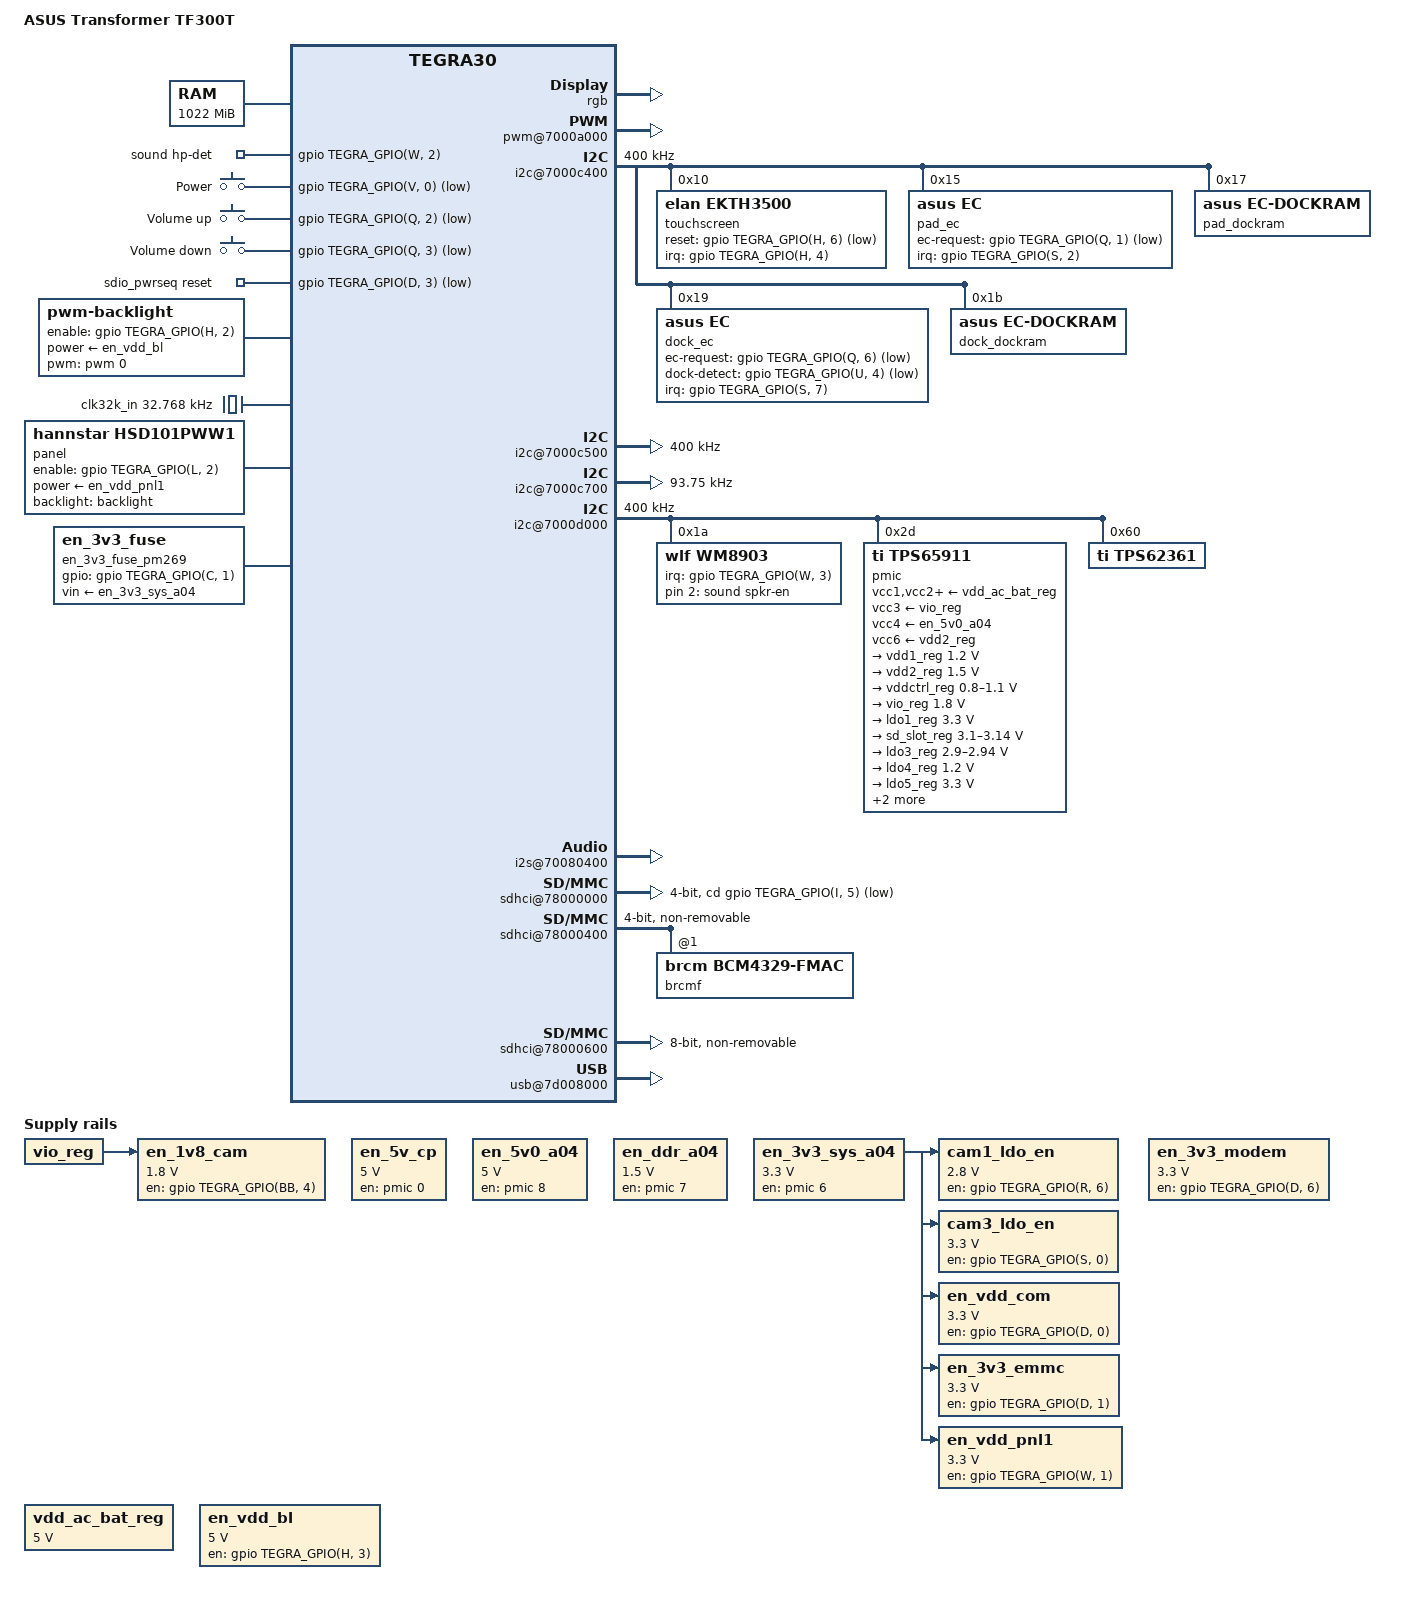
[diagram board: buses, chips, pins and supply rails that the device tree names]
/dts-v1/;

#include "tegra30.dtsi"

/ {
	model = "ASUS Transformer TF300T";
	compatible = "asus,tf300t", "nvidia,tegra30";

	memory {
		reg = <0x80000000 0x3FE00000>;
	};

	/*pcie-controller@00003000 {
		status = "okay";

		/* AVDD_PEXA and VDD_PEXA inputs are grounded on Cardhu. * /
		avdd-pexb-supply = <&ldo1_reg>;
		vdd-pexb-supply = <&ldo1_reg>;
		avdd-pex-pll-supply = <&ldo1_reg>;
		hvdd-pex-supply = <&pex_hvdd_3v3_reg>;
		vddio-pex-ctl-supply = <&sys_3v3_reg>;
		avdd-plle-supply = <&ldo2_reg>;

		pci@1,0 {
			nvidia,num-lanes = <4>;
		};

		pci@2,0 {
			nvidia,num-lanes = <1>;
		};

		pci@3,0 {
			status = "okay";
			nvidia,num-lanes = <1>;
		};
	};*/

	/* FIXME: broken */
	/delete-node/ cache-controller@50043000;

	cache-controller@50043000 {
		compatible = "arm,pl310-cache-nonsecure";
		reg = <0x50043000 0x1000>;
		arm,data-latency = <6 6 2>;
		arm,tag-latency = <5 5 2>;
		cache-unified;
		cache-level = <2>;
	};

	firmware {
		trusted-foundations {
			compatible = "tlm,trusted-foundations";
			tlm,version-major = <2>;
			tlm,version-minor = <8>;
		};
	};

	host1x@50000000 {
		dc@54200000 {
			rgb {
				status = "okay";

				nvidia,panel = <&panel>;
			};
		};
	};

	/*pinmux@70000868 {
		pinctrl-names = "default";
		pinctrl-0 = <&state_default>;

		state_default: pinmux {
			sdmmc1_clk_pz0 {
				nvidia,pins = "sdmmc1_clk_pz0";
				nvidia,function = "sdmmc1";
				nvidia,pull = <TEGRA_PIN_PULL_NONE>;
				nvidia,tristate = <TEGRA_PIN_DISABLE>;
				nvidia,enable-input = <TEGRA_PIN_ENABLE>;
			};
			sdmmc1_cmd_pz1 {
				nvidia,pins = "sdmmc1_cmd_pz1";
				nvidia,function = "sdmmc1";
				nvidia,pull = <TEGRA_PIN_PULL_UP>;
				nvidia,tristate = <TEGRA_PIN_DISABLE>;
				nvidia,enable-input = <TEGRA_PIN_ENABLE>;
			};
			sdmmc1_dat3_py4 {
				nvidia,pins = "sdmmc1_dat3_py4";
				nvidia,function = "sdmmc1";
				nvidia,pull = <TEGRA_PIN_PULL_UP>;
				nvidia,tristate = <TEGRA_PIN_DISABLE>;
				nvidia,enable-input = <TEGRA_PIN_ENABLE>;
			};
			sdmmc1_dat2_py5 {
				nvidia,pins = "sdmmc1_dat2_py5";
				nvidia,function = "sdmmc1";
				nvidia,pull = <TEGRA_PIN_PULL_UP>;
				nvidia,tristate = <TEGRA_PIN_DISABLE>;
				nvidia,enable-input = <TEGRA_PIN_ENABLE>;
			};
			sdmmc1_dat1_py6 {
				nvidia,pins = "sdmmc1_dat1_py6";
				nvidia,function = "sdmmc1";
				nvidia,pull = <TEGRA_PIN_PULL_UP>;
				nvidia,tristate = <TEGRA_PIN_DISABLE>;
				nvidia,enable-input = <TEGRA_PIN_ENABLE>;
			};
			sdmmc1_dat0_py7 {
				nvidia,pins = "sdmmc1_dat0_py7";
				nvidia,function = "sdmmc1";
				nvidia,pull = <TEGRA_PIN_PULL_UP>;
				nvidia,tristate = <TEGRA_PIN_DISABLE>;
				nvidia,enable-input = <TEGRA_PIN_ENABLE>;
			};
			sdmmc3_clk_pa6 {
				nvidia,pins = "sdmmc3_clk_pa6";
				nvidia,function = "sdmmc3";
				nvidia,pull = <TEGRA_PIN_PULL_NONE>;
				nvidia,tristate = <TEGRA_PIN_DISABLE>;
				nvidia,enable-input = <TEGRA_PIN_ENABLE>;
			};
			sdmmc3_cmd_pa7 {
				nvidia,pins = "sdmmc3_cmd_pa7";
				nvidia,function = "sdmmc3";
				nvidia,pull = <TEGRA_PIN_PULL_UP>;
				nvidia,tristate = <TEGRA_PIN_DISABLE>;
				nvidia,enable-input = <TEGRA_PIN_ENABLE>;
			};
			sdmmc3_dat0_pb7 {
				nvidia,pins = "sdmmc3_dat0_pb7";
				nvidia,function = "sdmmc3";
				nvidia,pull = <TEGRA_PIN_PULL_UP>;
				nvidia,tristate = <TEGRA_PIN_DISABLE>;
				nvidia,enable-input = <TEGRA_PIN_ENABLE>;
			};
			sdmmc3_dat1_pb6 {
				nvidia,pins = "sdmmc3_dat1_pb6";
				nvidia,function = "sdmmc3";
				nvidia,pull = <TEGRA_PIN_PULL_UP>;
				nvidia,tristate = <TEGRA_PIN_DISABLE>;
				nvidia,enable-input = <TEGRA_PIN_ENABLE>;
			};
			sdmmc3_dat2_pb5 {
				nvidia,pins = "sdmmc3_dat2_pb5";
				nvidia,function = "sdmmc3";
				nvidia,pull = <TEGRA_PIN_PULL_UP>;
				nvidia,tristate = <TEGRA_PIN_DISABLE>;
				nvidia,enable-input = <TEGRA_PIN_ENABLE>;
			};
			sdmmc3_dat3_pb4 {
				nvidia,pins = "sdmmc3_dat3_pb4";
				nvidia,function = "sdmmc3";
				nvidia,pull = <TEGRA_PIN_PULL_UP>;
				nvidia,tristate = <TEGRA_PIN_DISABLE>;
				nvidia,enable-input = <TEGRA_PIN_ENABLE>;
			};
			sdmmc3_dat6_pd3 {
				nvidia,pins = "sdmmc3_dat6_pd3";
				nvidia,function = "sdmmc3";
				nvidia,pull = <TEGRA_PIN_PULL_UP>;
				nvidia,tristate = <TEGRA_PIN_DISABLE>;
				/* WLAN RESET * /
				nvidia,enable-input = <TEGRA_PIN_ENABLE>;
				/*nvidia,enable-input = <TEGRA_PIN_DISABLE>;* /
			};
			sdmmc3_dat7_pd4 {
				nvidia,pins = "sdmmc3_dat7_pd4";
				nvidia,function = "sdmmc3";
				nvidia,pull = <TEGRA_PIN_PULL_UP>;
				nvidia,tristate = <TEGRA_PIN_DISABLE>;
				/* WLAN POWER * /
				nvidia,enable-input = <TEGRA_PIN_ENABLE>;
				/*nvidia,enable-input = <TEGRA_PIN_DISABLE>;* /
			};
			sdmmc4_clk_pcc4 {
				nvidia,pins = "sdmmc4_clk_pcc4";
				nvidia,function = "sdmmc4";
				nvidia,pull = <TEGRA_PIN_PULL_NONE>;
				nvidia,tristate = <TEGRA_PIN_DISABLE>;
				nvidia,enable-input = <TEGRA_PIN_ENABLE>;
			};
			sdmmc4_cmd_pt7 {
				nvidia,pins = "sdmmc4_cmd_pt7";
				nvidia,function = "sdmmc4";
				nvidia,pull = <TEGRA_PIN_PULL_UP>;
				nvidia,tristate = <TEGRA_PIN_DISABLE>;
				nvidia,enable-input = <TEGRA_PIN_ENABLE>;
			};
			sdmmc4_dat0_paa0 {
				nvidia,pins = "sdmmc4_dat0_paa0";
				nvidia,function = "sdmmc4";
				nvidia,pull = <TEGRA_PIN_PULL_UP>;
				nvidia,tristate = <TEGRA_PIN_DISABLE>;
				nvidia,enable-input = <TEGRA_PIN_ENABLE>;
			};
			sdmmc4_dat1_paa1 {
				nvidia,pins = "sdmmc4_dat1_paa1";
				nvidia,function = "sdmmc4";
				nvidia,pull = <TEGRA_PIN_PULL_UP>;
				nvidia,tristate = <TEGRA_PIN_DISABLE>;
				nvidia,enable-input = <TEGRA_PIN_ENABLE>;
			};
			sdmmc4_dat2_paa2 {
				nvidia,pins = "sdmmc4_dat2_paa2";
				nvidia,function = "sdmmc4";
				nvidia,pull = <TEGRA_PIN_PULL_UP>;
				nvidia,tristate = <TEGRA_PIN_DISABLE>;
				nvidia,enable-input = <TEGRA_PIN_ENABLE>;
			};
			sdmmc4_dat3_paa3 {
				nvidia,pins = "sdmmc4_dat3_paa3";
				nvidia,function = "sdmmc4";
				nvidia,pull = <TEGRA_PIN_PULL_UP>;
				nvidia,tristate = <TEGRA_PIN_DISABLE>;
				nvidia,enable-input = <TEGRA_PIN_ENABLE>;
			};
			sdmmc4_dat4_paa4 {
				nvidia,pins = "sdmmc4_dat4_paa4";
				nvidia,function = "sdmmc4";
				nvidia,pull = <TEGRA_PIN_PULL_UP>;
				nvidia,tristate = <TEGRA_PIN_DISABLE>;
				nvidia,enable-input = <TEGRA_PIN_ENABLE>;
			};
			sdmmc4_dat5_paa5 {
				nvidia,pins = "sdmmc4_dat5_paa5";
				nvidia,function = "sdmmc4";
				nvidia,pull = <TEGRA_PIN_PULL_UP>;
				nvidia,tristate = <TEGRA_PIN_DISABLE>;
				nvidia,enable-input = <TEGRA_PIN_ENABLE>;
			};
			sdmmc4_dat6_paa6 {
				nvidia,pins = "sdmmc4_dat6_paa6";
				nvidia,function = "sdmmc4";
				nvidia,pull = <TEGRA_PIN_PULL_UP>;
				nvidia,tristate = <TEGRA_PIN_DISABLE>;
				nvidia,enable-input = <TEGRA_PIN_ENABLE>;
			};
			sdmmc4_dat7_paa7 {
				nvidia,pins = "sdmmc4_dat7_paa7";
				nvidia,function = "sdmmc4";
				nvidia,pull = <TEGRA_PIN_PULL_UP>;
				nvidia,tristate = <TEGRA_PIN_DISABLE>;
				nvidia,enable-input = <TEGRA_PIN_ENABLE>;
			};
			sdmmc4_rst_n_pcc3 {
				nvidia,pins = "sdmmc4_rst_n_pcc3";
				nvidia,function = "rsvd1";
				nvidia,pull = <TEGRA_PIN_PULL_DOWN>;
				nvidia,tristate = <TEGRA_PIN_DISABLE>;
				nvidia,enable-input = <TEGRA_PIN_ENABLE>;
			};
			gen1_i2c_scl_pc4 {
				nvidia,pins = "gen1_i2c_scl_pc4";
				nvidia,function = "i2c1";
				nvidia,pull = <TEGRA_PIN_PULL_NONE>;
				nvidia,tristate = <TEGRA_PIN_DISABLE>;
				nvidia,enable-input = <TEGRA_PIN_ENABLE>;
				nvidia,lock = <TEGRA_PIN_DISABLE>;
				nvidia,open-drain = <TEGRA_PIN_ENABLE>;
			};
			gen1_i2c_sda_pc5 {
				nvidia,pins = "gen1_i2c_sda_pc5";
				nvidia,function = "i2c1";
				nvidia,pull = <TEGRA_PIN_PULL_NONE>;
				nvidia,tristate = <TEGRA_PIN_DISABLE>;
				nvidia,enable-input = <TEGRA_PIN_ENABLE>;
				nvidia,lock = <TEGRA_PIN_DISABLE>;
				nvidia,open-drain = <TEGRA_PIN_ENABLE>;
			};
			gen2_i2c_scl_pt5 {
				nvidia,pins = "gen2_i2c_scl_pt5";
				nvidia,function = "i2c2";
				nvidia,pull = <TEGRA_PIN_PULL_NONE>;
				nvidia,tristate = <TEGRA_PIN_DISABLE>;
				nvidia,enable-input = <TEGRA_PIN_ENABLE>;
				nvidia,lock = <TEGRA_PIN_DISABLE>;
				nvidia,open-drain = <TEGRA_PIN_ENABLE>;
			};
			gen2_i2c_sda_pt6 {
				nvidia,pins = "gen2_i2c_sda_pt6";
				nvidia,function = "i2c2";
				nvidia,pull = <TEGRA_PIN_PULL_NONE>;
				nvidia,tristate = <TEGRA_PIN_DISABLE>;
				nvidia,enable-input = <TEGRA_PIN_ENABLE>;
				nvidia,lock = <TEGRA_PIN_DISABLE>;
				nvidia,open-drain = <TEGRA_PIN_ENABLE>;
			};
			cam_i2c_scl_pbb1 {
				nvidia,pins = "cam_i2c_scl_pbb1";
				nvidia,function = "i2c3";
				nvidia,pull = <TEGRA_PIN_PULL_NONE>;
				nvidia,tristate = <TEGRA_PIN_DISABLE>;
				nvidia,enable-input = <TEGRA_PIN_ENABLE>;
				nvidia,lock = <TEGRA_PIN_DISABLE>;
				nvidia,open-drain = <TEGRA_PIN_ENABLE>;
			};
			cam_i2c_sda_pbb2 {
				nvidia,pins = "cam_i2c_sda_pbb2";
				nvidia,function = "i2c3";
				nvidia,pull = <TEGRA_PIN_PULL_NONE>;
				nvidia,tristate = <TEGRA_PIN_DISABLE>;
				nvidia,enable-input = <TEGRA_PIN_ENABLE>;
				nvidia,lock = <TEGRA_PIN_DISABLE>;
				nvidia,open-drain = <TEGRA_PIN_ENABLE>;
			};
			ddc_scl_pv4 {
				nvidia,pins = "ddc_scl_pv4";
				nvidia,function = "i2c4";
				nvidia,pull = <TEGRA_PIN_PULL_NONE>;
				nvidia,tristate = <TEGRA_PIN_DISABLE>;
				nvidia,enable-input = <TEGRA_PIN_ENABLE>;
				nvidia,lock = <TEGRA_PIN_DISABLE>;
				nvidia,open-drain = <TEGRA_PIN_ENABLE>;
			};
			ddc_sda_pv5 {
				nvidia,pins = "ddc_sda_pv5";
				nvidia,function = "i2c4";
				nvidia,pull = <TEGRA_PIN_PULL_NONE>;
				nvidia,tristate = <TEGRA_PIN_DISABLE>;
				nvidia,enable-input = <TEGRA_PIN_ENABLE>;
				nvidia,lock = <TEGRA_PIN_DISABLE>;
				nvidia,open-drain = <TEGRA_PIN_ENABLE>;
			};
			pwr_i2c_scl_pz6 {
				nvidia,pins = "pwr_i2c_scl_pz6";
				nvidia,function = "i2cpwr";
				nvidia,pull = <TEGRA_PIN_PULL_NONE>;
				nvidia,tristate = <TEGRA_PIN_DISABLE>;
				nvidia,enable-input = <TEGRA_PIN_ENABLE>;
				nvidia,lock = <TEGRA_PIN_DISABLE>;
				nvidia,open-drain = <TEGRA_PIN_ENABLE>;
			};
			pwr_i2c_sda_pz7 {
				nvidia,pins = "pwr_i2c_sda_pz7";
				nvidia,function = "i2cpwr";
				nvidia,pull = <TEGRA_PIN_PULL_NONE>;
				nvidia,tristate = <TEGRA_PIN_DISABLE>;
				nvidia,enable-input = <TEGRA_PIN_ENABLE>;
				nvidia,lock = <TEGRA_PIN_DISABLE>;
				nvidia,open-drain = <TEGRA_PIN_ENABLE>;
			};
			hdmi_cec_pee3 {
				nvidia,pins = "hdmi_cec_pee3";
				nvidia,function = "cec";
				nvidia,pull = <TEGRA_PIN_PULL_NONE>;
				nvidia,tristate = <TEGRA_PIN_DISABLE>;
				nvidia,enable-input = <TEGRA_PIN_ENABLE>;
			};
			ulpi_data0_po1 {
				nvidia,pins = "ulpi_data0_po1";
				nvidia,function = "uarta";
				nvidia,pull = <TEGRA_PIN_PULL_NONE>;
				nvidia,tristate = <TEGRA_PIN_DISABLE>;
				nvidia,enable-input = <TEGRA_PIN_DISABLE>;
			};
			ulpi_data1_po2 {
				nvidia,pins = "ulpi_data1_po2";
				nvidia,function = "uarta";
				nvidia,pull = <TEGRA_PIN_PULL_DOWN>;
				nvidia,tristate = <TEGRA_PIN_ENABLE>;
				nvidia,enable-input = <TEGRA_PIN_ENABLE>;
			};
			ulpi_data2_po3 {
				nvidia,pins = "ulpi_data2_po3";
				nvidia,function = "uarta";
				nvidia,pull = <TEGRA_PIN_PULL_NONE>;
				nvidia,tristate = <TEGRA_PIN_DISABLE>;
				nvidia,enable-input = <TEGRA_PIN_ENABLE>;
			};
			ulpi_data3_po4 {
				nvidia,pins = "ulpi_data3_po4";
				nvidia,function = "uarta";
				nvidia,pull = <TEGRA_PIN_PULL_NONE>;
				nvidia,tristate = <TEGRA_PIN_DISABLE>;
				nvidia,enable-input = <TEGRA_PIN_ENABLE>;
			};
			ulpi_data4_po5 {
				nvidia,pins = "ulpi_data4_po5";
				nvidia,function = "uarta";
				nvidia,pull = <TEGRA_PIN_PULL_NONE>;
				nvidia,tristate = <TEGRA_PIN_DISABLE>;
				nvidia,enable-input = <TEGRA_PIN_ENABLE>;
			};
			ulpi_data5_po6 {
				nvidia,pins = "ulpi_data5_po6";
				nvidia,function = "uarta";
				nvidia,pull = <TEGRA_PIN_PULL_NONE>;
				nvidia,tristate = <TEGRA_PIN_ENABLE>;
				nvidia,enable-input = <TEGRA_PIN_ENABLE>;
			};
			ulpi_data6_po7 {
				nvidia,pins = "ulpi_data6_po7";
				nvidia,function = "uarta";
				nvidia,pull = <TEGRA_PIN_PULL_NONE>;
				nvidia,tristate = <TEGRA_PIN_DISABLE>;
				nvidia,enable-input = <TEGRA_PIN_ENABLE>;
			};
			ulpi_data7_po0 {
				nvidia,pins = "ulpi_data7_po0";
				nvidia,function = "uarta";
				nvidia,pull = <TEGRA_PIN_PULL_NONE>;
				nvidia,tristate = <TEGRA_PIN_DISABLE>;
				nvidia,enable-input = <TEGRA_PIN_ENABLE>;
			};
			ulpi_nxt_py2 {
				nvidia,pins = "ulpi_nxt_py2";
				nvidia,function = "uartd";
				nvidia,pull = <TEGRA_PIN_PULL_NONE>;
				nvidia,tristate = <TEGRA_PIN_ENABLE>;
				nvidia,enable-input = <TEGRA_PIN_ENABLE>;
			};
			ulpi_stp_py3 {
				nvidia,pins = "ulpi_stp_py3";
				nvidia,function = "uartd";
				nvidia,pull = <TEGRA_PIN_PULL_NONE>;
				nvidia,tristate = <TEGRA_PIN_ENABLE>;
				nvidia,enable-input = <TEGRA_PIN_DISABLE>;
			};
			dap3_fs_pp0 {
				nvidia,pins = "dap3_fs_pp0";
				nvidia,function = "i2s2";
				nvidia,pull = <TEGRA_PIN_PULL_NONE>;
				nvidia,tristate = <TEGRA_PIN_ENABLE>;
				nvidia,enable-input = <TEGRA_PIN_ENABLE>;
			};
			dap3_din_pp1 {
				nvidia,pins = "dap3_din_pp1";
				nvidia,function = "i2s2";
				nvidia,pull = <TEGRA_PIN_PULL_NONE>;
				nvidia,tristate = <TEGRA_PIN_ENABLE>;
				nvidia,enable-input = <TEGRA_PIN_ENABLE>;
			};
			dap3_dout_pp2 {
				nvidia,pins = "dap3_dout_pp2";
				nvidia,function = "i2s2";
				nvidia,pull = <TEGRA_PIN_PULL_NONE>;
				nvidia,tristate = <TEGRA_PIN_DISABLE>;
				nvidia,enable-input = <TEGRA_PIN_ENABLE>;
			};
			dap3_sclk_pp3 {
				nvidia,pins = "dap3_sclk_pp3";
				nvidia,function = "i2s2";
				nvidia,pull = <TEGRA_PIN_PULL_NONE>;
				nvidia,tristate = <TEGRA_PIN_DISABLE>;
				nvidia,enable-input = <TEGRA_PIN_ENABLE>;
			};
			pv2 {
				nvidia,pins = "pv2";
				nvidia,function = "rsvd1";
				nvidia,pull = <TEGRA_PIN_PULL_NONE>;
				nvidia,tristate = <TEGRA_PIN_DISABLE>;
				nvidia,enable-input = <TEGRA_PIN_DISABLE>;
			};
			pv3 {
				nvidia,pins = "pv3";
				nvidia,function = "rsvd1";
				nvidia,pull = <TEGRA_PIN_PULL_NONE>;
				nvidia,tristate = <TEGRA_PIN_ENABLE>;
				nvidia,enable-input = <TEGRA_PIN_DISABLE>;
			};
			clk2_out_pw5 {
				nvidia,pins = "clk2_out_pw5";
				nvidia,function = "extperiph2";
				nvidia,pull = <TEGRA_PIN_PULL_NONE>;
				nvidia,tristate = <TEGRA_PIN_DISABLE>;
				nvidia,enable-input = <TEGRA_PIN_ENABLE>;
			};
			clk2_req_pcc5 {
				nvidia,pins = "clk2_req_pcc5";
				nvidia,function = "dap";
				nvidia,pull = <TEGRA_PIN_PULL_NONE>;
				nvidia,tristate = <TEGRA_PIN_DISABLE>;
				nvidia,enable-input = <TEGRA_PIN_ENABLE>;
			};
			lcd_pwr1_pc1 {
				nvidia,pins = "lcd_pwr1_pc1";
				nvidia,function = "displaya";
				nvidia,pull = <TEGRA_PIN_PULL_NONE>;
				nvidia,tristate = <TEGRA_PIN_DISABLE>;
				nvidia,enable-input = <TEGRA_PIN_ENABLE>;
			};
			lcd_sdin_pz2 {
				nvidia,pins = "lcd_sdin_pz2";
				nvidia,function = "displaya";
				nvidia,pull = <TEGRA_PIN_PULL_NONE>;
				nvidia,tristate = <TEGRA_PIN_DISABLE>;
				nvidia,enable-input = <TEGRA_PIN_ENABLE>;
			};
			lcd_sdout_pn5 {
				nvidia,pins = "lcd_sdout_pn5";
				nvidia,function = "displaya";
				nvidia,pull = <TEGRA_PIN_PULL_NONE>;
				nvidia,tristate = <TEGRA_PIN_ENABLE>;
				nvidia,enable-input = <TEGRA_PIN_ENABLE>;
			};
			lcd_wr_n_pz3 {
				nvidia,pins = "lcd_wr_n_pz3";
				nvidia,function = "displaya";
				nvidia,pull = <TEGRA_PIN_PULL_NONE>;
				nvidia,tristate = <TEGRA_PIN_ENABLE>;
				nvidia,enable-input = <TEGRA_PIN_ENABLE>;
			};
			lcd_dc0_pn6 {
				nvidia,pins = "lcd_dc0_pn6";
				nvidia,function = "displaya";
				nvidia,pull = <TEGRA_PIN_PULL_NONE>;
				nvidia,tristate = <TEGRA_PIN_DISABLE>;
				nvidia,enable-input = <TEGRA_PIN_ENABLE>;
			};
			lcd_pwr0_pb2 {
				nvidia,pins = "lcd_pwr0_pb2";
				nvidia,function = "displaya";
				nvidia,pull = <TEGRA_PIN_PULL_NONE>;
				nvidia,tristate = <TEGRA_PIN_DISABLE>;
				nvidia,enable-input = <TEGRA_PIN_ENABLE>;
			};
			lcd_pclk_pb3 {
				nvidia,pins = "lcd_pclk_pb3";
				nvidia,function = "displaya";
				nvidia,pull = <TEGRA_PIN_PULL_NONE>;
				nvidia,tristate = <TEGRA_PIN_DISABLE>;
				nvidia,enable-input = <TEGRA_PIN_ENABLE>;
			};
			lcd_de_pj1 {
				nvidia,pins = "lcd_de_pj1";
				nvidia,function = "displaya";
				nvidia,pull = <TEGRA_PIN_PULL_NONE>;
				nvidia,tristate = <TEGRA_PIN_DISABLE>;
				nvidia,enable-input = <TEGRA_PIN_ENABLE>;
			};
			lcd_hsync_pj3 {
				nvidia,pins = "lcd_hsync_pj3";
				nvidia,function = "displaya";
				nvidia,pull = <TEGRA_PIN_PULL_NONE>;
				nvidia,tristate = <TEGRA_PIN_DISABLE>;
				nvidia,enable-input = <TEGRA_PIN_ENABLE>;
			};
			lcd_vsync_pj4 {
				nvidia,pins = "lcd_vsync_pj4";
				nvidia,function = "displaya";
				nvidia,pull = <TEGRA_PIN_PULL_NONE>;
				nvidia,tristate = <TEGRA_PIN_DISABLE>;
				nvidia,enable-input = <TEGRA_PIN_ENABLE>;
			};
			lcd_d0_pe0 {
				nvidia,pins = "lcd_d0_pe0";
				nvidia,function = "displaya";
				nvidia,pull = <TEGRA_PIN_PULL_NONE>;
				nvidia,tristate = <TEGRA_PIN_DISABLE>;
				nvidia,enable-input = <TEGRA_PIN_ENABLE>;
			};
			lcd_d1_pe1 {
				nvidia,pins = "lcd_d1_pe1";
				nvidia,function = "displaya";
				nvidia,pull = <TEGRA_PIN_PULL_NONE>;
				nvidia,tristate = <TEGRA_PIN_DISABLE>;
				nvidia,enable-input = <TEGRA_PIN_ENABLE>;
			};
			lcd_d2_pe2 {
				nvidia,pins = "lcd_d2_pe2";
				nvidia,function = "displaya";
				nvidia,pull = <TEGRA_PIN_PULL_NONE>;
				nvidia,tristate = <TEGRA_PIN_DISABLE>;
				nvidia,enable-input = <TEGRA_PIN_ENABLE>;
			};
			lcd_d3_pe3 {
				nvidia,pins = "lcd_d3_pe3";
				nvidia,function = "displaya";
				nvidia,pull = <TEGRA_PIN_PULL_NONE>;
				nvidia,tristate = <TEGRA_PIN_DISABLE>;
				nvidia,enable-input = <TEGRA_PIN_ENABLE>;
			};
			lcd_d4_pe4 {
				nvidia,pins = "lcd_d4_pe4";
				nvidia,function = "displaya";
				nvidia,pull = <TEGRA_PIN_PULL_NONE>;
				nvidia,tristate = <TEGRA_PIN_DISABLE>;
				nvidia,enable-input = <TEGRA_PIN_ENABLE>;
			};
			lcd_d5_pe5 {
				nvidia,pins = "lcd_d5_pe5";
				nvidia,function = "displaya";
				nvidia,pull = <TEGRA_PIN_PULL_NONE>;
				nvidia,tristate = <TEGRA_PIN_DISABLE>;
				nvidia,enable-input = <TEGRA_PIN_ENABLE>;
			};
			lcd_d6_pe6 {
				nvidia,pins = "lcd_d6_pe6";
				nvidia,function = "displaya";
				nvidia,pull = <TEGRA_PIN_PULL_NONE>;
				nvidia,tristate = <TEGRA_PIN_DISABLE>;
				nvidia,enable-input = <TEGRA_PIN_ENABLE>;
			};
			lcd_d7_pe7 {
				nvidia,pins = "lcd_d7_pe7";
				nvidia,function = "displaya";
				nvidia,pull = <TEGRA_PIN_PULL_NONE>;
				nvidia,tristate = <TEGRA_PIN_DISABLE>;
				nvidia,enable-input = <TEGRA_PIN_ENABLE>;
			};
			lcd_d8_pf0 {
				nvidia,pins = "lcd_d8_pf0";
				nvidia,function = "displaya";
				nvidia,pull = <TEGRA_PIN_PULL_NONE>;
				nvidia,tristate = <TEGRA_PIN_DISABLE>;
				nvidia,enable-input = <TEGRA_PIN_ENABLE>;
			};
			lcd_d9_pf1 {
				nvidia,pins = "lcd_d9_pf1";
				nvidia,function = "displaya";
				nvidia,pull = <TEGRA_PIN_PULL_NONE>;
				nvidia,tristate = <TEGRA_PIN_DISABLE>;
				nvidia,enable-input = <TEGRA_PIN_ENABLE>;
			};
			lcd_d10_pf2 {
				nvidia,pins = "lcd_d10_pf2";
				nvidia,function = "displaya";
				nvidia,pull = <TEGRA_PIN_PULL_NONE>;
				nvidia,tristate = <TEGRA_PIN_DISABLE>;
				nvidia,enable-input = <TEGRA_PIN_ENABLE>;
			};
			lcd_d11_pf3 {
				nvidia,pins = "lcd_d11_pf3";
				nvidia,function = "displaya";
				nvidia,pull = <TEGRA_PIN_PULL_NONE>;
				nvidia,tristate = <TEGRA_PIN_DISABLE>;
				nvidia,enable-input = <TEGRA_PIN_ENABLE>;
			};
			lcd_d12_pf4 {
				nvidia,pins = "lcd_d12_pf4";
				nvidia,function = "displaya";
				nvidia,pull = <TEGRA_PIN_PULL_NONE>;
				nvidia,tristate = <TEGRA_PIN_DISABLE>;
				nvidia,enable-input = <TEGRA_PIN_ENABLE>;
			};
			lcd_d13_pf5 {
				nvidia,pins = "lcd_d13_pf5";
				nvidia,function = "displaya";
				nvidia,pull = <TEGRA_PIN_PULL_NONE>;
				nvidia,tristate = <TEGRA_PIN_DISABLE>;
				nvidia,enable-input = <TEGRA_PIN_ENABLE>;
			};
			lcd_d14_pf6 {
				nvidia,pins = "lcd_d14_pf6";
				nvidia,function = "displaya";
				nvidia,pull = <TEGRA_PIN_PULL_NONE>;
				nvidia,tristate = <TEGRA_PIN_DISABLE>;
				nvidia,enable-input = <TEGRA_PIN_ENABLE>;
			};
			lcd_d15_pf7 {
				nvidia,pins = "lcd_d15_pf7";
				nvidia,function = "displaya";
				nvidia,pull = <TEGRA_PIN_PULL_NONE>;
				nvidia,tristate = <TEGRA_PIN_DISABLE>;
				nvidia,enable-input = <TEGRA_PIN_ENABLE>;
			};
			lcd_d16_pm0 {
				nvidia,pins = "lcd_d16_pm0";
				nvidia,function = "displaya";
				nvidia,pull = <TEGRA_PIN_PULL_NONE>;
				nvidia,tristate = <TEGRA_PIN_DISABLE>;
				nvidia,enable-input = <TEGRA_PIN_ENABLE>;
			};
			lcd_d17_pm1 {
				nvidia,pins = "lcd_d17_pm1";
				nvidia,function = "displaya";
				nvidia,pull = <TEGRA_PIN_PULL_NONE>;
				nvidia,tristate = <TEGRA_PIN_DISABLE>;
				nvidia,enable-input = <TEGRA_PIN_ENABLE>;
			};
			lcd_d18_pm2 {
				nvidia,pins = "lcd_d18_pm2";
				nvidia,function = "displaya";
				nvidia,pull = <TEGRA_PIN_PULL_NONE>;
				nvidia,tristate = <TEGRA_PIN_DISABLE>;
				nvidia,enable-input = <TEGRA_PIN_ENABLE>;
			};
			lcd_d19_pm3 {
				nvidia,pins = "lcd_d19_pm3";
				nvidia,function = "displaya";
				nvidia,pull = <TEGRA_PIN_PULL_NONE>;
				nvidia,tristate = <TEGRA_PIN_DISABLE>;
				nvidia,enable-input = <TEGRA_PIN_ENABLE>;
			};
			lcd_d20_pm4 {
				nvidia,pins = "lcd_d20_pm4";
				nvidia,function = "displaya";
				nvidia,pull = <TEGRA_PIN_PULL_NONE>;
				nvidia,tristate = <TEGRA_PIN_DISABLE>;
				nvidia,enable-input = <TEGRA_PIN_ENABLE>;
			};
			lcd_d21_pm5 {
				nvidia,pins = "lcd_d21_pm5";
				nvidia,function = "displaya";
				nvidia,pull = <TEGRA_PIN_PULL_NONE>;
				nvidia,tristate = <TEGRA_PIN_DISABLE>;
				nvidia,enable-input = <TEGRA_PIN_ENABLE>;
			};
			lcd_d22_pm6 {
				nvidia,pins = "lcd_d22_pm6";
				nvidia,function = "displaya";
				nvidia,pull = <TEGRA_PIN_PULL_NONE>;
				nvidia,tristate = <TEGRA_PIN_DISABLE>;
				nvidia,enable-input = <TEGRA_PIN_ENABLE>;
			};
			lcd_d23_pm7 {
				nvidia,pins = "lcd_d23_pm7";
				nvidia,function = "displaya";
				nvidia,pull = <TEGRA_PIN_PULL_NONE>;
				nvidia,tristate = <TEGRA_PIN_DISABLE>;
				nvidia,enable-input = <TEGRA_PIN_ENABLE>;
			};
			crt_hsync_pv6 {
				nvidia,pins = "crt_hsync_pv6";
				nvidia,function = "crt";
				nvidia,pull = <TEGRA_PIN_PULL_NONE>;
				nvidia,tristate = <TEGRA_PIN_ENABLE>;
				nvidia,enable-input = <TEGRA_PIN_DISABLE>;
			};
			crt_vsync_pv7 {
				nvidia,pins = "crt_vsync_pv7";
				nvidia,function = "crt";
				nvidia,pull = <TEGRA_PIN_PULL_NONE>;
				nvidia,tristate = <TEGRA_PIN_ENABLE>;
				nvidia,enable-input = <TEGRA_PIN_DISABLE>;
			};
			vi_d0_pt4 {
				nvidia,pins = "vi_d0_pt4";
				nvidia,function = "rsvd1";
				nvidia,pull = <TEGRA_PIN_PULL_NONE>;
				nvidia,tristate = <TEGRA_PIN_DISABLE>;
				nvidia,enable-input = <TEGRA_PIN_ENABLE>;
			};
			vi_d1_pd5 {
				nvidia,pins = "vi_d1_pd5";
				nvidia,function = "sdmmc2";
				nvidia,pull = <TEGRA_PIN_PULL_NONE>;
				nvidia,tristate = <TEGRA_PIN_DISABLE>;
				nvidia,enable-input = <TEGRA_PIN_ENABLE>;
			};
			vi_d2_pl0 {
				nvidia,pins = "vi_d2_pl0";
				nvidia,function = "sdmmc2";
				nvidia,pull = <TEGRA_PIN_PULL_NONE>;
				nvidia,tristate = <TEGRA_PIN_DISABLE>;
				nvidia,enable-input = <TEGRA_PIN_ENABLE>;
			};
			vi_d3_pl1 {
				nvidia,pins = "vi_d3_pl1";
				nvidia,function = "sdmmc2";
				nvidia,pull = <TEGRA_PIN_PULL_NONE>;
				nvidia,tristate = <TEGRA_PIN_DISABLE>;
				nvidia,enable-input = <TEGRA_PIN_ENABLE>;
			};
			vi_d4_pl2 {
				nvidia,pins = "vi_d4_pl2";
				nvidia,function = "vi";
				nvidia,pull = <TEGRA_PIN_PULL_NONE>;
				nvidia,tristate = <TEGRA_PIN_DISABLE>;
				nvidia,enable-input = <TEGRA_PIN_DISABLE>;
			};
			vi_d5_pl3 {
				nvidia,pins = "vi_d5_pl3";
				nvidia,function = "sdmmc2";
				nvidia,pull = <TEGRA_PIN_PULL_NONE>;
				nvidia,tristate = <TEGRA_PIN_DISABLE>;
				nvidia,enable-input = <TEGRA_PIN_ENABLE>;
			};
			vi_d7_pl5 {
				nvidia,pins = "vi_d7_pl5";
				nvidia,function = "sdmmc2";
				nvidia,pull = <TEGRA_PIN_PULL_NONE>;
				nvidia,tristate = <TEGRA_PIN_DISABLE>;
				nvidia,enable-input = <TEGRA_PIN_ENABLE>;
			};
			vi_d10_pt2 {
				nvidia,pins = "vi_d10_pt2";
				nvidia,function = "rsvd1";
				nvidia,pull = <TEGRA_PIN_PULL_NONE>;
				nvidia,tristate = <TEGRA_PIN_DISABLE>;
				nvidia,enable-input = <TEGRA_PIN_ENABLE>;
			};
			vi_mclk_pt1 {
				nvidia,pins = "vi_mclk_pt1";
				nvidia,function = "vi";
				nvidia,pull = <TEGRA_PIN_PULL_UP>;
				nvidia,tristate = <TEGRA_PIN_DISABLE>;
				nvidia,enable-input = <TEGRA_PIN_ENABLE>;
			};
			uart2_rxd_pc3 {
				nvidia,pins = "uart2_rxd_pc3";
				nvidia,function = "irda";
				nvidia,pull = <TEGRA_PIN_PULL_NONE>;
				nvidia,tristate = <TEGRA_PIN_DISABLE>;
				nvidia,enable-input = <TEGRA_PIN_ENABLE>;
			};
			uart2_txd_pc2 {
				nvidia,pins = "uart2_txd_pc2";
				nvidia,function = "irda";
				nvidia,pull = <TEGRA_PIN_PULL_NONE>;
				nvidia,tristate = <TEGRA_PIN_DISABLE>;
				nvidia,enable-input = <TEGRA_PIN_DISABLE>;
			};
			uart2_rts_n_pj6 {
				nvidia,pins = "uart2_rts_n_pj6";
				nvidia,function = "uartb";
				nvidia,pull = <TEGRA_PIN_PULL_NONE>;
				nvidia,tristate = <TEGRA_PIN_DISABLE>;
				nvidia,enable-input = <TEGRA_PIN_DISABLE>;
			};
			uart2_cts_n_pj5 {
				nvidia,pins = "uart2_cts_n_pj5";
				nvidia,function = "uartb";
				nvidia,pull = <TEGRA_PIN_PULL_NONE>;
				nvidia,tristate = <TEGRA_PIN_DISABLE>;
				nvidia,enable-input = <TEGRA_PIN_ENABLE>;
			};
			uart3_txd_pw6 {
				nvidia,pins = "uart3_txd_pw6";
				nvidia,function = "uartc";
				nvidia,pull = <TEGRA_PIN_PULL_NONE>;
				nvidia,tristate = <TEGRA_PIN_DISABLE>;
				nvidia,enable-input = <TEGRA_PIN_DISABLE>;
			};
			uart3_rxd_pw7 {
				nvidia,pins = "uart3_rxd_pw7";
				nvidia,function = "uartc";
				nvidia,pull = <TEGRA_PIN_PULL_NONE>;
				nvidia,tristate = <TEGRA_PIN_DISABLE>;
				nvidia,enable-input = <TEGRA_PIN_ENABLE>;
			};
			uart3_cts_n_pa1 {
				nvidia,pins = "uart3_cts_n_pa1";
				nvidia,function = "uartc";
				nvidia,pull = <TEGRA_PIN_PULL_NONE>;
				nvidia,tristate = <TEGRA_PIN_DISABLE>;
				nvidia,enable-input = <TEGRA_PIN_ENABLE>;
			};
			uart3_rts_n_pc0 {
				nvidia,pins = "uart3_rts_n_pc0";
				nvidia,function = "uartc";
				nvidia,pull = <TEGRA_PIN_PULL_NONE>;
				nvidia,tristate = <TEGRA_PIN_DISABLE>;
				nvidia,enable-input = <TEGRA_PIN_DISABLE>;
			};
			pu0 {
				nvidia,pins = "pu0";
				nvidia,function = "rsvd1";
				nvidia,pull = <TEGRA_PIN_PULL_NONE>;
				nvidia,tristate = <TEGRA_PIN_DISABLE>;
				nvidia,enable-input = <TEGRA_PIN_ENABLE>;
			};
			pu1 {
				nvidia,pins = "pu1";
				nvidia,function = "rsvd1";
				nvidia,pull = <TEGRA_PIN_PULL_NONE>;
				nvidia,tristate = <TEGRA_PIN_DISABLE>;
				nvidia,enable-input = <TEGRA_PIN_DISABLE>;
			};
			pu2 {
				nvidia,pins = "pu2";
				nvidia,function = "rsvd1";
				nvidia,pull = <TEGRA_PIN_PULL_NONE>;
				nvidia,tristate = <TEGRA_PIN_DISABLE>;
				nvidia,enable-input = <TEGRA_PIN_ENABLE>;
			};
			pu5 {
				nvidia,pins = "pu5";
				nvidia,function = "pwm2";
				nvidia,pull = <TEGRA_PIN_PULL_NONE>;
				nvidia,tristate = <TEGRA_PIN_DISABLE>;
				nvidia,enable-input = <TEGRA_PIN_ENABLE>;
			};
			pu6 {
				nvidia,pins = "pu6";
				nvidia,function = "rsvd1";
				nvidia,pull = <TEGRA_PIN_PULL_DOWN>;
				nvidia,tristate = <TEGRA_PIN_DISABLE>;
				nvidia,enable-input = <TEGRA_PIN_ENABLE>;
			};
			dap4_fs_pp4 {
				nvidia,pins = "dap4_fs_pp4";
				nvidia,function = "i2s3";
				nvidia,pull = <TEGRA_PIN_PULL_NONE>;
				nvidia,tristate = <TEGRA_PIN_DISABLE>;
				nvidia,enable-input = <TEGRA_PIN_ENABLE>;
			};
			dap4_din_pp5 {
				nvidia,pins = "dap4_din_pp5";
				nvidia,function = "i2s3";
				nvidia,pull = <TEGRA_PIN_PULL_NONE>;
				nvidia,tristate = <TEGRA_PIN_DISABLE>;
				nvidia,enable-input = <TEGRA_PIN_ENABLE>;
			};
			dap4_dout_pp6 {
				nvidia,pins = "dap4_dout_pp6";
				nvidia,function = "i2s3";
				nvidia,pull = <TEGRA_PIN_PULL_NONE>;
				nvidia,tristate = <TEGRA_PIN_DISABLE>;
				nvidia,enable-input = <TEGRA_PIN_ENABLE>;
			};
			dap4_sclk_pp7 {
				nvidia,pins = "dap4_sclk_pp7";
				nvidia,function = "i2s3";
				nvidia,pull = <TEGRA_PIN_PULL_NONE>;
				nvidia,tristate = <TEGRA_PIN_DISABLE>;
				nvidia,enable-input = <TEGRA_PIN_ENABLE>;
			};
			clk3_out_pee0 {
				nvidia,pins = "clk3_out_pee0";
				nvidia,function = "extperiph3";
				nvidia,pull = <TEGRA_PIN_PULL_NONE>;
				nvidia,tristate = <TEGRA_PIN_ENABLE>;
				nvidia,enable-input = <TEGRA_PIN_DISABLE>;
			};
			clk3_req_pee1 {
				nvidia,pins = "clk3_req_pee1";
				nvidia,function = "dev3";
				nvidia,pull = <TEGRA_PIN_PULL_NONE>;
				nvidia,tristate = <TEGRA_PIN_ENABLE>;
				nvidia,enable-input = <TEGRA_PIN_ENABLE>;
			};
			kb_row10_ps2 {
				nvidia,pins = "kb_row10_ps2";
				nvidia,function = "kbc";
				nvidia,pull = <TEGRA_PIN_PULL_UP>;
				nvidia,tristate = <TEGRA_PIN_DISABLE>;
				nvidia,enable-input = <TEGRA_PIN_ENABLE>;
			};
			kb_row15_ps7 {
				nvidia,pins = "kb_row15_ps7";
				nvidia,function = "kbc";
				nvidia,pull = <TEGRA_PIN_PULL_UP>;
				nvidia,tristate = <TEGRA_PIN_DISABLE>;
				nvidia,enable-input = <TEGRA_PIN_ENABLE>;
			};
			pu4 {
				nvidia,pins = "pu4";
				nvidia,function = "rsvd1";
				nvidia,pull = <TEGRA_PIN_PULL_UP>;
				nvidia,tristate = <TEGRA_PIN_DISABLE>;
				nvidia,enable-input = <TEGRA_PIN_ENABLE>;
			};
			kb_row14_ps6 {
				nvidia,pins = "kb_row14_ps6";
				nvidia,function = "kbc";
				nvidia,pull = <TEGRA_PIN_PULL_UP>;
				nvidia,tristate = <TEGRA_PIN_DISABLE>;
				nvidia,enable-input = <TEGRA_PIN_ENABLE>;
			};
			gmi_ad8_ph0 {
				nvidia,pins = "gmi_ad8_ph0";
				nvidia,function = "pwm0";
				nvidia,pull = <TEGRA_PIN_PULL_NONE>;
				nvidia,tristate = <TEGRA_PIN_DISABLE>;
				nvidia,enable-input = <TEGRA_PIN_DISABLE>;
			};
			gmi_a16_pj7 {
				nvidia,pins = "gmi_a16_pj7";
				nvidia,function = "spi4";
				nvidia,pull = <TEGRA_PIN_PULL_NONE>;
				nvidia,tristate = <TEGRA_PIN_ENABLE>;
				nvidia,enable-input = <TEGRA_PIN_ENABLE>;
			};
			gmi_a17_pb0 {
				nvidia,pins = "gmi_a17_pb0";
				nvidia,function = "spi4";
				nvidia,pull = <TEGRA_PIN_PULL_NONE>;
				nvidia,tristate = <TEGRA_PIN_ENABLE>;
				nvidia,enable-input = <TEGRA_PIN_ENABLE>;
			};
			gmi_a18_pb1 {
				nvidia,pins = "gmi_a18_pb1";
				nvidia,function = "spi4";
				nvidia,pull = <TEGRA_PIN_PULL_UP>;
				nvidia,tristate = <TEGRA_PIN_DISABLE>;
				nvidia,enable-input = <TEGRA_PIN_ENABLE>;
			};
			gmi_a19_pk7 {
				nvidia,pins = "gmi_a19_pk7";
				nvidia,function = "spi4";
				nvidia,pull = <TEGRA_PIN_PULL_NONE>;
				nvidia,tristate = <TEGRA_PIN_DISABLE>;
				nvidia,enable-input = <TEGRA_PIN_ENABLE>;
			};
			cam_mclk_pcc0 {
				nvidia,pins = "cam_mclk_pcc0";
				nvidia,function = "vi_alt2";
				nvidia,pull = <TEGRA_PIN_PULL_UP>;
				nvidia,tristate = <TEGRA_PIN_DISABLE>;
				nvidia,enable-input = <TEGRA_PIN_ENABLE>;
			};
			pcc1 {
				nvidia,pins = "pcc1";
				nvidia,function = "rsvd1";
				nvidia,pull = <TEGRA_PIN_PULL_NONE>;
				nvidia,tristate = <TEGRA_PIN_ENABLE>;
				nvidia,enable-input = <TEGRA_PIN_ENABLE>;
			};
			pbb0 {
				nvidia,pins = "pbb0";
				nvidia,function = "rsvd1";
				nvidia,pull = <TEGRA_PIN_PULL_NONE>;
				nvidia,tristate = <TEGRA_PIN_DISABLE>;
				nvidia,enable-input = <TEGRA_PIN_ENABLE>;
			};
			pbb5 {
				nvidia,pins = "pbb5";
				nvidia,function = "vgp5";
				nvidia,pull = <TEGRA_PIN_PULL_NONE>;
				nvidia,tristate = <TEGRA_PIN_DISABLE>;
				nvidia,enable-input = <TEGRA_PIN_ENABLE>;
			};
			pbb6 {
				nvidia,pins = "pbb6";
				nvidia,function = "vgp6";
				nvidia,pull = <TEGRA_PIN_PULL_NONE>;
				nvidia,tristate = <TEGRA_PIN_DISABLE>;
				nvidia,enable-input = <TEGRA_PIN_ENABLE>;
			};
			pcc2 {
				nvidia,pins = "pcc2";
				nvidia,function = "i2s4";
				nvidia,pull = <TEGRA_PIN_PULL_NONE>;
				nvidia,tristate = <TEGRA_PIN_DISABLE>;
				nvidia,enable-input = <TEGRA_PIN_ENABLE>;
			};
			jtag_rtck_pu7 {
				nvidia,pins = "jtag_rtck_pu7";
				nvidia,function = "rtck";
				nvidia,pull = <TEGRA_PIN_PULL_NONE>;
				nvidia,tristate = <TEGRA_PIN_DISABLE>;
				nvidia,enable-input = <TEGRA_PIN_DISABLE>;
			};
			kb_row1_pr1 {
				nvidia,pins = "kb_row1_pr1";
				nvidia,function = "kbc";
				nvidia,pull = <TEGRA_PIN_PULL_UP>;
				nvidia,tristate = <TEGRA_PIN_DISABLE>;
				nvidia,enable-input = <TEGRA_PIN_ENABLE>;
			};
			kb_row3_pr3 {
				nvidia,pins = "kb_row3_pr3";
				nvidia,function = "kbc";
				nvidia,pull = <TEGRA_PIN_PULL_UP>;
				nvidia,tristate = <TEGRA_PIN_DISABLE>;
				nvidia,enable-input = <TEGRA_PIN_ENABLE>;
			};
			kb_col0_pq0 {
				nvidia,pins = "kb_col0_pq0";
				nvidia,function = "kbc";
				nvidia,pull = <TEGRA_PIN_PULL_NONE>;
				nvidia,tristate = <TEGRA_PIN_ENABLE>;
				nvidia,enable-input = <TEGRA_PIN_DISABLE>;
			};
			kb_col1_pq1 {
				nvidia,pins = "kb_col1_pq1";
				nvidia,function = "kbc";
				nvidia,pull = <TEGRA_PIN_PULL_UP>;
				nvidia,tristate = <TEGRA_PIN_DISABLE>;
				nvidia,enable-input = <TEGRA_PIN_ENABLE>;
			};
			kb_row0_pr0 {
				nvidia,pins = "kb_row0_pr0";
				nvidia,function = "rsvd";
				nvidia,pull = <TEGRA_PIN_PULL_UP>;
				nvidia,tristate = <TEGRA_PIN_DISABLE>;
				nvidia,enable-input = <TEGRA_PIN_DISABLE>;
			};
			pv0 {
				nvidia,pins = "pv0";
				nvidia,function = "rsvd";
				nvidia,pull = <TEGRA_PIN_PULL_UP>;
				nvidia,tristate = <TEGRA_PIN_ENABLE>;
				nvidia,enable-input = <TEGRA_PIN_ENABLE>;
			};
			kb_col2_pq2 {
				nvidia,pins = "kb_col2_pq2";
				nvidia,function = "rsvd";
				nvidia,pull = <TEGRA_PIN_PULL_UP>;
				nvidia,tristate = <TEGRA_PIN_ENABLE>;
				nvidia,enable-input = <TEGRA_PIN_ENABLE>;
			};
			kb_col3_pq3 {
				nvidia,pins = "kb_col3_pq3";
				nvidia,function = "rsvd";
				nvidia,pull = <TEGRA_PIN_PULL_UP>;
				nvidia,tristate = <TEGRA_PIN_ENABLE>;
				nvidia,enable-input = <TEGRA_PIN_ENABLE>;
			};
			kb_row4_pr4 {
				nvidia,pins = "kb_row4_pr4";
				nvidia,function = "kbc";
				nvidia,pull = <TEGRA_PIN_PULL_NONE>;
				nvidia,tristate = <TEGRA_PIN_ENABLE>;
				nvidia,enable-input = <TEGRA_PIN_ENABLE>;
			};
			kb_row5_pr5 {
				nvidia,pins = "kb_row5_pr5";
				nvidia,function = "kbc";
				nvidia,pull = <TEGRA_PIN_PULL_NONE>;
				nvidia,tristate = <TEGRA_PIN_ENABLE>;
				nvidia,enable-input = <TEGRA_PIN_ENABLE>;
			};
			kb_col4_pq4 {
				nvidia,pins = "kb_col4_pq4";
				nvidia,function = "kbc";
				nvidia,pull = <TEGRA_PIN_PULL_NONE>;
				nvidia,tristate = <TEGRA_PIN_ENABLE>;
				nvidia,enable-input = <TEGRA_PIN_ENABLE>;
			};
			kb_col7_pq7 {
				nvidia,pins = "kb_col7_pq7";
				nvidia,function = "kbc";
				nvidia,pull = <TEGRA_PIN_PULL_NONE>;
				nvidia,tristate = <TEGRA_PIN_ENABLE>;
				nvidia,enable-input = <TEGRA_PIN_ENABLE>;
			};
			kb_row2_pr2 {
				nvidia,pins = "kb_row2_pr2";
				nvidia,function = "kbc";
				nvidia,pull = <TEGRA_PIN_PULL_NONE>;
				nvidia,tristate = <TEGRA_PIN_ENABLE>;
				nvidia,enable-input = <TEGRA_PIN_ENABLE>;
			};
			kb_col5_pq5 {
				nvidia,pins = "kb_col5_pq5";
				nvidia,function = "kbc";
				nvidia,pull = <TEGRA_PIN_PULL_NONE>;
				nvidia,tristate = <TEGRA_PIN_ENABLE>;
				nvidia,enable-input = <TEGRA_PIN_ENABLE>;
			};
			gmi_cs0_n_pj0 {
				nvidia,pins = "gmi_cs0_n_pj0";
				nvidia,function = "rsvd1";
				nvidia,pull = <TEGRA_PIN_PULL_NONE>;
				nvidia,tristate = <TEGRA_PIN_ENABLE>;
				nvidia,enable-input = <TEGRA_PIN_ENABLE>;
			};
			gmi_cs1_n_pj2 {
				nvidia,pins = "gmi_cs1_n_pj2";
				nvidia,function = "rsvd1";
				nvidia,pull = <TEGRA_PIN_PULL_NONE>;
				nvidia,tristate = <TEGRA_PIN_ENABLE>;
				nvidia,enable-input = <TEGRA_PIN_ENABLE>;
			};
			gmi_wait_pi7 {
				nvidia,pins = "gmi_wait_pi7";
				nvidia,function = "rsvd1";
				nvidia,pull = <TEGRA_PIN_PULL_NONE>;
				nvidia,tristate = <TEGRA_PIN_ENABLE>;
				nvidia,enable-input = <TEGRA_PIN_ENABLE>;
			};
			gmi_wp_n_pc7 {
				nvidia,pins = "gmi_wp_n_pc7";
				nvidia,function = "rsvd1";
				nvidia,pull = <TEGRA_PIN_PULL_NONE>;
				nvidia,tristate = <TEGRA_PIN_ENABLE>;
				nvidia,enable-input = <TEGRA_PIN_ENABLE>;
			};
			kb_row7_pr7 {
				nvidia,pins = "kb_row7_pr7";
				nvidia,function = "kbc";
				nvidia,pull = <TEGRA_PIN_PULL_UP>;
				nvidia,tristate = <TEGRA_PIN_DISABLE>;
				nvidia,enable-input = <TEGRA_PIN_ENABLE>;
			};
			gmi_cs4_n_pk2 {
				nvidia,pins = "gmi_cs4_n_pk2";
				nvidia,function = "gmi";
				nvidia,pull = <TEGRA_PIN_PULL_NONE>;
				nvidia,tristate = <TEGRA_PIN_ENABLE>;
				nvidia,enable-input = <TEGRA_PIN_ENABLE>;
			};
			gmi_cs6_n_pi3 {
				nvidia,pins = "gmi_cs6_n_pi3";
				nvidia,function = "gmi";
				nvidia,pull = <TEGRA_PIN_PULL_NONE>;
				nvidia,tristate = <TEGRA_PIN_ENABLE>;
				nvidia,enable-input = <TEGRA_PIN_ENABLE>;
			};
			gmi_cs2_n_pk3 {
				nvidia,pins = "gmi_cs2_n_pk3";
				nvidia,function = "rsvd1";
				nvidia,pull = <TEGRA_PIN_PULL_NONE>;
				nvidia,tristate = <TEGRA_PIN_ENABLE>;
				nvidia,enable-input = <TEGRA_PIN_ENABLE>;
			};
			gmi_cs3_n_pk4 {
				nvidia,pins = "gmi_cs3_n_pk4";
				nvidia,function = "rsvd1";
				nvidia,pull = <TEGRA_PIN_PULL_NONE>;
				nvidia,tristate = <TEGRA_PIN_ENABLE>;
				nvidia,enable-input = <TEGRA_PIN_ENABLE>;
			};
			clk_32k_out_pa0 {
				nvidia,pins = "clk_32k_out_pa0";
				nvidia,function = "blink";
				nvidia,pull = <TEGRA_PIN_PULL_NONE>;
				nvidia,tristate = <TEGRA_PIN_DISABLE>;
				nvidia,enable-input = <TEGRA_PIN_DISABLE>;
			};
			sys_clk_req_pz5 {
				nvidia,pins = "sys_clk_req_pz5";
				nvidia,function = "sysclk";
				nvidia,pull = <TEGRA_PIN_PULL_NONE>;
				nvidia,tristate = <TEGRA_PIN_DISABLE>;
				nvidia,enable-input = <TEGRA_PIN_DISABLE>;
			};
			owr {
				nvidia,pins = "owr";
				nvidia,function = "owr";
				nvidia,pull = <TEGRA_PIN_PULL_NONE>;
				nvidia,tristate = <TEGRA_PIN_DISABLE>;
				nvidia,enable-input = <TEGRA_PIN_ENABLE>;
			};
			dap1_fs_pn0 {
				nvidia,pins = "dap1_fs_pn0";
				nvidia,function = "i2s0";
				nvidia,pull = <TEGRA_PIN_PULL_NONE>;
				nvidia,tristate = <TEGRA_PIN_ENABLE>;
				nvidia,enable-input = <TEGRA_PIN_ENABLE>;
			};
			dap1_din_pn1 {
				nvidia,pins = "dap1_din_pn1";
				nvidia,function = "i2s0";
				nvidia,pull = <TEGRA_PIN_PULL_NONE>;
				nvidia,tristate = <TEGRA_PIN_ENABLE>;
				nvidia,enable-input = <TEGRA_PIN_ENABLE>;
			};
			dap1_dout_pn2 {
				nvidia,pins = "dap1_dout_pn2";
				nvidia,function = "i2s0";
				nvidia,pull = <TEGRA_PIN_PULL_NONE>;
				nvidia,tristate = <TEGRA_PIN_ENABLE>;
				nvidia,enable-input = <TEGRA_PIN_ENABLE>;
			};
			dap1_sclk_pn3 {
				nvidia,pins = "dap1_sclk_pn3";
				nvidia,function = "i2s0";
				nvidia,pull = <TEGRA_PIN_PULL_NONE>;
				nvidia,tristate = <TEGRA_PIN_ENABLE>;
				nvidia,enable-input = <TEGRA_PIN_ENABLE>;
			};
			clk1_req_pee2 {
				nvidia,pins = "clk1_req_pee2";
				nvidia,function = "dap";
				nvidia,pull = <TEGRA_PIN_PULL_NONE>;
				nvidia,tristate = <TEGRA_PIN_DISABLE>;
				nvidia,enable-input = <TEGRA_PIN_ENABLE>;
			};
			clk1_out_pw4 {
				nvidia,pins = "clk1_out_pw4";
				nvidia,function = "extperiph1";
				nvidia,pull = <TEGRA_PIN_PULL_NONE>;
				nvidia,tristate = <TEGRA_PIN_DISABLE>;
				nvidia,enable-input = <TEGRA_PIN_ENABLE>;
			};
			spdif_in_pk6 {
				nvidia,pins = "spdif_in_pk6";
				nvidia,function = "spdif";
				nvidia,pull = <TEGRA_PIN_PULL_NONE>;
				nvidia,tristate = <TEGRA_PIN_ENABLE>;
				nvidia,enable-input = <TEGRA_PIN_ENABLE>;
			};
			spdif_out_pk5 {
				nvidia,pins = "spdif_out_pk5";
				nvidia,function = "spdif";
				nvidia,pull = <TEGRA_PIN_PULL_NONE>;
				nvidia,tristate = <TEGRA_PIN_ENABLE>;
				nvidia,enable-input = <TEGRA_PIN_DISABLE>;
			};
			dap2_fs_pa2 {
				nvidia,pins = "dap2_fs_pa2";
				nvidia,function = "i2s1";
				nvidia,pull = <TEGRA_PIN_PULL_NONE>;
				nvidia,tristate = <TEGRA_PIN_DISABLE>;
				nvidia,enable-input = <TEGRA_PIN_ENABLE>;
			};
			dap2_din_pa4 {
				nvidia,pins = "dap2_din_pa4";
				nvidia,function = "i2s1";
				nvidia,pull = <TEGRA_PIN_PULL_NONE>;
				nvidia,tristate = <TEGRA_PIN_DISABLE>;
				nvidia,enable-input = <TEGRA_PIN_ENABLE>;
			};
			dap2_dout_pa5 {
				nvidia,pins = "dap2_dout_pa5";
				nvidia,function = "i2s1";
				nvidia,pull = <TEGRA_PIN_PULL_NONE>;
				nvidia,tristate = <TEGRA_PIN_DISABLE>;
				nvidia,enable-input = <TEGRA_PIN_ENABLE>;
			};
			dap2_sclk_pa3 {
				nvidia,pins = "dap2_sclk_pa3";
				nvidia,function = "i2s1";
				nvidia,pull = <TEGRA_PIN_PULL_NONE>;
				nvidia,tristate = <TEGRA_PIN_DISABLE>;
				nvidia,enable-input = <TEGRA_PIN_ENABLE>;
			};
			spi2_cs1_n_pw2 {
				nvidia,pins = "spi2_cs1_n_pw2";
				nvidia,function = "spi2";
				nvidia,pull = <TEGRA_PIN_PULL_UP>;
				nvidia,tristate = <TEGRA_PIN_DISABLE>;
				nvidia,enable-input = <TEGRA_PIN_ENABLE>;
			};
			spi1_mosi_px4 {
				nvidia,pins = "spi1_mosi_px4";
				nvidia,function = "spi1";
				nvidia,pull = <TEGRA_PIN_PULL_NONE>;
				nvidia,tristate = <TEGRA_PIN_ENABLE>;
				nvidia,enable-input = <TEGRA_PIN_ENABLE>;
			};
			spi1_sck_px5 {
				nvidia,pins = "spi1_sck_px5";
				nvidia,function = "spi1";
				nvidia,pull = <TEGRA_PIN_PULL_NONE>;
				nvidia,tristate = <TEGRA_PIN_ENABLE>;
				nvidia,enable-input = <TEGRA_PIN_ENABLE>;
			};
			spi1_cs0_n_px6 {
				nvidia,pins = "spi1_cs0_n_px6";
				nvidia,function = "spi1";
				nvidia,pull = <TEGRA_PIN_PULL_NONE>;
				nvidia,tristate = <TEGRA_PIN_ENABLE>;
				nvidia,enable-input = <TEGRA_PIN_ENABLE>;
			};
			spi1_miso_px7 {
				nvidia,pins = "spi1_miso_px7";
				nvidia,function = "spi1";
				nvidia,pull = <TEGRA_PIN_PULL_NONE>;
				nvidia,tristate = <TEGRA_PIN_ENABLE>;
				nvidia,enable-input = <TEGRA_PIN_ENABLE>;
			};
			pex_l0_prsnt_n_pdd0 {
				nvidia,pins = "pex_l0_prsnt_n_pdd0";
				nvidia,function = "pcie";
				nvidia,pull = <TEGRA_PIN_PULL_NONE>;
				nvidia,tristate = <TEGRA_PIN_DISABLE>;
				nvidia,enable-input = <TEGRA_PIN_ENABLE>;
			};
			pex_l0_rst_n_pdd1 {
				nvidia,pins = "pex_l0_rst_n_pdd1";
				nvidia,function = "pcie";
				nvidia,pull = <TEGRA_PIN_PULL_NONE>;
				nvidia,tristate = <TEGRA_PIN_DISABLE>;
				nvidia,enable-input = <TEGRA_PIN_DISABLE>;
			};
			pex_l0_clkreq_n_pdd2 {
				nvidia,pins = "pex_l0_clkreq_n_pdd2";
				nvidia,function = "pcie";
				nvidia,pull = <TEGRA_PIN_PULL_NONE>;
				nvidia,tristate = <TEGRA_PIN_DISABLE>;
				nvidia,enable-input = <TEGRA_PIN_ENABLE>;
			};
			pex_wake_n_pdd3 {
				nvidia,pins = "pex_wake_n_pdd3";
				nvidia,function = "pcie";
				nvidia,pull = <TEGRA_PIN_PULL_NONE>;
				nvidia,tristate = <TEGRA_PIN_DISABLE>;
				nvidia,enable-input = <TEGRA_PIN_ENABLE>;
			};
			pex_l1_prsnt_n_pdd4 {
				nvidia,pins = "pex_l1_prsnt_n_pdd4";
				nvidia,function = "pcie";
				nvidia,pull = <TEGRA_PIN_PULL_NONE>;
				nvidia,tristate = <TEGRA_PIN_DISABLE>;
				nvidia,enable-input = <TEGRA_PIN_ENABLE>;
			};
			pex_l1_rst_n_pdd5 {
				nvidia,pins = "pex_l1_rst_n_pdd5";
				nvidia,function = "pcie";
				nvidia,pull = <TEGRA_PIN_PULL_NONE>;
				nvidia,tristate = <TEGRA_PIN_DISABLE>;
				nvidia,enable-input = <TEGRA_PIN_DISABLE>;
			};
			pex_l1_clkreq_n_pdd6 {
				nvidia,pins = "pex_l1_clkreq_n_pdd6";
				nvidia,function = "pcie";
				nvidia,pull = <TEGRA_PIN_PULL_NONE>;
				nvidia,tristate = <TEGRA_PIN_DISABLE>;
				nvidia,enable-input = <TEGRA_PIN_ENABLE>;
			};
			pex_l2_prsnt_n_pdd7 {
				nvidia,pins = "pex_l2_prsnt_n_pdd7";
				nvidia,function = "pcie";
				nvidia,pull = <TEGRA_PIN_PULL_NONE>;
				nvidia,tristate = <TEGRA_PIN_DISABLE>;
				nvidia,enable-input = <TEGRA_PIN_ENABLE>;
			};
			pex_l2_rst_n_pcc6 {
				nvidia,pins = "pex_l2_rst_n_pcc6";
				nvidia,function = "pcie";
				nvidia,pull = <TEGRA_PIN_PULL_NONE>;
				nvidia,tristate = <TEGRA_PIN_DISABLE>;
				nvidia,enable-input = <TEGRA_PIN_DISABLE>;
			};
			pex_l2_clkreq_n_pcc7 {
				nvidia,pins = "pex_l2_clkreq_n_pcc7";
				nvidia,function = "pcie";
				nvidia,pull = <TEGRA_PIN_PULL_NONE>;
				nvidia,tristate = <TEGRA_PIN_DISABLE>;
				nvidia,enable-input = <TEGRA_PIN_ENABLE>;
			};
			hdmi_int_pn7 {
				nvidia,pins = "hdmi_int_pn7";
				nvidia,function = "rsvd";
				nvidia,pull = <TEGRA_PIN_PULL_NONE>;
				nvidia,tristate = <TEGRA_PIN_ENABLE>;
				nvidia,enable-input = <TEGRA_PIN_ENABLE>;
			};
			gmi_iordy_pi5 {
				nvidia,pins = "gmi_iordy_pi5";
				nvidia,function = "rsvd1";
				nvidia,pull = <TEGRA_PIN_PULL_UP>;
				nvidia,tristate = <TEGRA_PIN_DISABLE>;
				nvidia,enable-input = <TEGRA_PIN_ENABLE>;
			};
			vi_d11_pt3 {
				nvidia,pins = "vi_d11_pt3";
				nvidia,function = "rsvd1";
				nvidia,pull = <TEGRA_PIN_PULL_UP>;
				nvidia,tristate = <TEGRA_PIN_DISABLE>;
				nvidia,enable-input = <TEGRA_PIN_ENABLE>;
			};
			gmi_ad12_ph4 {
				nvidia,pins = "gmi_ad12_ph4";
				nvidia,function = "nand";
				nvidia,pull = <TEGRA_PIN_PULL_UP>;
				nvidia,tristate = <TEGRA_PIN_DISABLE>;
				nvidia,enable-input = <TEGRA_PIN_ENABLE>;
			};
			gmi_ad14_ph6 {
				nvidia,pins = "gmi_ad14_ph6";
				nvidia,function = "nand";
				nvidia,pull = <TEGRA_PIN_PULL_NONE>;
				nvidia,tristate = <TEGRA_PIN_DISABLE>;
				nvidia,enable-input = <TEGRA_PIN_DISABLE>;
			};
			gmi_ad15_ph7 {
				nvidia,pins = "gmi_ad15_ph7";
				nvidia,function = "nand";
				nvidia,pull = <TEGRA_PIN_PULL_DOWN>;
				nvidia,tristate = <TEGRA_PIN_DISABLE>;
				nvidia,enable-input = <TEGRA_PIN_DISABLE>;
			};
			spi2_sck_px2 {
				nvidia,pins = "spi2_sck_px2";
				nvidia,function = "spi2";
				nvidia,pull = <TEGRA_PIN_PULL_NONE>;
				nvidia,tristate = <TEGRA_PIN_DISABLE>;
				nvidia,enable-input = <TEGRA_PIN_ENABLE>;
			};
			pbb4 {
				nvidia,pins = "pbb4";
				nvidia,function = "vgp4";
				nvidia,pull = <TEGRA_PIN_PULL_NONE>;
				nvidia,tristate = <TEGRA_PIN_DISABLE>;
				nvidia,enable-input = <TEGRA_PIN_ENABLE>;
			};
			kb_row8_ps0 {
				nvidia,pins = "kb_row8_ps0";
				nvidia,function = "kbc";
				nvidia,pull = <TEGRA_PIN_PULL_UP>;
				nvidia,tristate = <TEGRA_PIN_DISABLE>;
				nvidia,enable-input = <TEGRA_PIN_ENABLE>;
			};
			sdmmc3_dat5_pd0 {
				nvidia,pins = "sdmmc3_dat5_pd0";
				nvidia,function = "sdmmc3";
				nvidia,pull = <TEGRA_PIN_PULL_UP>;
				nvidia,tristate = <TEGRA_PIN_DISABLE>;
				nvidia,enable-input = <TEGRA_PIN_ENABLE>;
			};
			sdmmc3_dat4_pd1 {
				nvidia,pins = "sdmmc3_dat4_pd1";
				nvidia,function = "sdmmc3";
				nvidia,pull = <TEGRA_PIN_PULL_UP>;
				nvidia,tristate = <TEGRA_PIN_DISABLE>;
				nvidia,enable-input = <TEGRA_PIN_ENABLE>;
			};
			vi_d6_pl4 {
				nvidia,pins = "vi_d6_pl4";
				nvidia,function = "vi";
				nvidia,pull = <TEGRA_PIN_PULL_NONE>;
				nvidia,tristate = <TEGRA_PIN_DISABLE>;
				nvidia,enable-input = <TEGRA_PIN_DISABLE>;
				nvidia,lock = <TEGRA_PIN_DISABLE>;
				nvidia,io-reset = <TEGRA_PIN_DISABLE>;
			};
			vi_d8_pl6 {
				nvidia,pins = "vi_d8_pl6";
				nvidia,function = "sdmmc2";
				nvidia,pull = <TEGRA_PIN_PULL_NONE>;
				nvidia,tristate = <TEGRA_PIN_DISABLE>;
				nvidia,enable-input = <TEGRA_PIN_ENABLE>;
				nvidia,lock = <TEGRA_PIN_DISABLE>;
				nvidia,io-reset = <TEGRA_PIN_DISABLE>;
			};
			vi_d9_pl7 {
				nvidia,pins = "vi_d9_pl7";
				nvidia,function = "sdmmc2";
				nvidia,pull = <TEGRA_PIN_PULL_NONE>;
				nvidia,tristate = <TEGRA_PIN_DISABLE>;
				nvidia,enable-input = <TEGRA_PIN_ENABLE>;
				nvidia,lock = <TEGRA_PIN_DISABLE>;
				nvidia,io-reset = <TEGRA_PIN_DISABLE>;
			};
			vi_pclk_pt0 {
				nvidia,pins = "vi_pclk_pt0";
				nvidia,function = "rsvd1";
				nvidia,pull = <TEGRA_PIN_PULL_UP>;
				nvidia,tristate = <TEGRA_PIN_ENABLE>;
				nvidia,enable-input = <TEGRA_PIN_ENABLE>;
				nvidia,lock = <TEGRA_PIN_DISABLE>;
				nvidia,io-reset = <TEGRA_PIN_DISABLE>;
			};
			vi_hsync_pd7 {
				nvidia,pins = "vi_hsync_pd7";
				nvidia,function = "rsvd1";
				nvidia,pull = <TEGRA_PIN_PULL_NONE>;
				nvidia,tristate = <TEGRA_PIN_DISABLE>;
				nvidia,enable-input = <TEGRA_PIN_ENABLE>;
				nvidia,lock = <TEGRA_PIN_DISABLE>;
				nvidia,io-reset = <TEGRA_PIN_DISABLE>;
			};
			vi_vsync_pd6 {
				nvidia,pins = "vi_vsync_pd6";
				nvidia,function = "rsvd1";
				nvidia,pull = <TEGRA_PIN_PULL_NONE>;
				nvidia,tristate = <TEGRA_PIN_DISABLE>;
				nvidia,enable-input = <TEGRA_PIN_ENABLE>;
				nvidia,lock = <TEGRA_PIN_DISABLE>;
				nvidia,io-reset = <TEGRA_PIN_DISABLE>;
			};
			lcd_cs0_n_pn4 {
				nvidia,pins = "lcd_cs0_n_pn4";
				nvidia,function = "displaya";
				nvidia,pull = <TEGRA_PIN_PULL_NONE>;
				nvidia,tristate = <TEGRA_PIN_ENABLE>;
				nvidia,enable-input = <TEGRA_PIN_ENABLE>;
			};
			kb_row12_ps4 {
				nvidia,pins = "kb_row12_ps4";
				nvidia,function = "kbc";
				nvidia,pull = <TEGRA_PIN_PULL_NONE>;
				nvidia,tristate = <TEGRA_PIN_ENABLE>;
				nvidia,enable-input = <TEGRA_PIN_ENABLE>;
			};
			kb_row13_ps5 {
				nvidia,pins = "kb_row13_ps5";
				nvidia,function = "kbc";
				nvidia,pull = <TEGRA_PIN_PULL_NONE>;
				nvidia,tristate = <TEGRA_PIN_ENABLE>;
				nvidia,enable-input = <TEGRA_PIN_ENABLE>;
			};
			pu3 {
				nvidia,pins = "pu3";
				nvidia,function = "rsvd1";
				nvidia,pull = <TEGRA_PIN_PULL_NONE>;
				nvidia,tristate = <TEGRA_PIN_DISABLE>;
				nvidia,enable-input = <TEGRA_PIN_DISABLE>;
			};
			gmi_rst_n_pi4 {
				nvidia,pins = "gmi_rst_n_pi4";
				nvidia,function = "nand";
				nvidia,pull = <TEGRA_PIN_PULL_UP>;
				nvidia,tristate = <TEGRA_PIN_DISABLE>;
				nvidia,enable-input = <TEGRA_PIN_ENABLE>;
			};
			gmi_adv_n_pk0 {
				nvidia,pins = "gmi_adv_n_pk0";
				nvidia,function = "nand";
				nvidia,pull = <TEGRA_PIN_PULL_NONE>;
				nvidia,tristate = <TEGRA_PIN_ENABLE>;
				nvidia,enable-input = <TEGRA_PIN_DISABLE>;
			};
			gmi_clk_pk1 {
				nvidia,pins = "gmi_clk_pk1";
				nvidia,function = "nand";
				nvidia,pull = <TEGRA_PIN_PULL_NONE>;
				nvidia,tristate = <TEGRA_PIN_ENABLE>;
				nvidia,enable-input = <TEGRA_PIN_DISABLE>;
			};
			gmi_cs7_n_pi6 {
				nvidia,pins = "gmi_cs7_n_pi6";
				nvidia,function = "nand";
				nvidia,pull = <TEGRA_PIN_PULL_UP>;
				nvidia,tristate = <TEGRA_PIN_DISABLE>;
				nvidia,enable-input = <TEGRA_PIN_ENABLE>;
			};
			gmi_ad0_pg0 {
				nvidia,pins = "gmi_ad0_pg0";
				nvidia,function = "nand";
				nvidia,pull = <TEGRA_PIN_PULL_NONE>;
				nvidia,tristate = <TEGRA_PIN_ENABLE>;
				nvidia,enable-input = <TEGRA_PIN_DISABLE>;
			};
			gmi_ad1_pg1 {
				nvidia,pins = "gmi_ad1_pg1";
				nvidia,function = "nand";
				nvidia,pull = <TEGRA_PIN_PULL_NONE>;
				nvidia,tristate = <TEGRA_PIN_ENABLE>;
				nvidia,enable-input = <TEGRA_PIN_DISABLE>;
			};
			gmi_ad2_pg2 {
				nvidia,pins = "gmi_ad2_pg2";
				nvidia,function = "nand";
				nvidia,pull = <TEGRA_PIN_PULL_NONE>;
				nvidia,tristate = <TEGRA_PIN_ENABLE>;
				nvidia,enable-input = <TEGRA_PIN_DISABLE>;
			};
			gmi_ad3_pg3 {
				nvidia,pins = "gmi_ad3_pg3";
				nvidia,function = "nand";
				nvidia,pull = <TEGRA_PIN_PULL_NONE>;
				nvidia,tristate = <TEGRA_PIN_ENABLE>;
				nvidia,enable-input = <TEGRA_PIN_DISABLE>;
			};
			gmi_ad6_pg6 {
				nvidia,pins = "gmi_ad6_pg6";
				nvidia,function = "nand";
				nvidia,pull = <TEGRA_PIN_PULL_NONE>;
				nvidia,tristate = <TEGRA_PIN_ENABLE>;
				nvidia,enable-input = <TEGRA_PIN_DISABLE>;
			};
			gmi_ad7_pg7 {
				nvidia,pins = "gmi_ad7_pg7";
				nvidia,function = "nand";
				nvidia,pull = <TEGRA_PIN_PULL_NONE>;
				nvidia,tristate = <TEGRA_PIN_ENABLE>;
				nvidia,enable-input = <TEGRA_PIN_DISABLE>;
			};
			gmi_ad11_ph3 {
				nvidia,pins = "gmi_ad11_ph3";
				nvidia,function = "nand";
				nvidia,pull = <TEGRA_PIN_PULL_NONE>;
				nvidia,tristate = <TEGRA_PIN_DISABLE>;
				nvidia,enable-input = <TEGRA_PIN_DISABLE>;
			};
			gmi_wr_n_pi0 {
				nvidia,pins = "gmi_wr_n_pi0";
				nvidia,function = "nand";
				nvidia,pull = <TEGRA_PIN_PULL_NONE>;
				nvidia,tristate = <TEGRA_PIN_ENABLE>;
				nvidia,enable-input = <TEGRA_PIN_DISABLE>;
			};
			gmi_oe_n_pi1 {
				nvidia,pins = "gmi_oe_n_pi1";
				nvidia,function = "nand";
				nvidia,pull = <TEGRA_PIN_PULL_NONE>;
				nvidia,tristate = <TEGRA_PIN_ENABLE>;
				nvidia,enable-input = <TEGRA_PIN_DISABLE>;
			};
			gmi_dqs_pi2 {
				nvidia,pins = "gmi_dqs_pi2";
				nvidia,function = "nand";
				nvidia,pull = <TEGRA_PIN_PULL_NONE>;
				nvidia,tristate = <TEGRA_PIN_ENABLE>;
				nvidia,enable-input = <TEGRA_PIN_DISABLE>;
			};
			gmi_ad4_pg4 {
				nvidia,pins = "gmi_ad4_pg4";
				nvidia,function = "nand";
				nvidia,pull = <TEGRA_PIN_PULL_NONE>;
				nvidia,tristate = <TEGRA_PIN_DISABLE>;
				nvidia,enable-input = <TEGRA_PIN_ENABLE>;
			};
			gmi_ad5_pg5 {
				nvidia,pins = "gmi_ad5_pg5";
				nvidia,function = "nand";
				nvidia,pull = <TEGRA_PIN_PULL_NONE>;
				nvidia,tristate = <TEGRA_PIN_DISABLE>;
				nvidia,enable-input = <TEGRA_PIN_ENABLE>;
			};
			gmi_ad10_ph2 {
				nvidia,pins = "gmi_ad10_ph2";
				nvidia,function = "nand";
				nvidia,pull = <TEGRA_PIN_PULL_NONE>;
				nvidia,tristate = <TEGRA_PIN_DISABLE>;
				nvidia,enable-input = <TEGRA_PIN_DISABLE>;
			};
			gmi_ad13_ph5 {
				nvidia,pins = "gmi_ad13_ph5";
				nvidia,function = "nand";
				nvidia,pull = <TEGRA_PIN_PULL_NONE>;
				nvidia,tristate = <TEGRA_PIN_DISABLE>;
				nvidia,enable-input = <TEGRA_PIN_ENABLE>;
			};
			ulpi_clk_py0 {
				nvidia,pins = "ulpi_clk_py0";
				nvidia,function = "uartd";
				nvidia,pull = <TEGRA_PIN_PULL_NONE>;
				nvidia,tristate = <TEGRA_PIN_ENABLE>;
				nvidia,enable-input = <TEGRA_PIN_DISABLE>;
			};
			ulpi_dir_py1 {
				nvidia,pins = "ulpi_dir_py1";
				nvidia,function = "uartd";
				nvidia,pull = <TEGRA_PIN_PULL_NONE>;
				nvidia,tristate = <TEGRA_PIN_ENABLE>;
				nvidia,enable-input = <TEGRA_PIN_DISABLE>;
			};
			lcd_pwr2_pc6 {
				nvidia,pins = "lcd_pwr2_pc6";
				nvidia,function = "displaya";
				nvidia,pull = <TEGRA_PIN_PULL_NONE>;
				nvidia,tristate = <TEGRA_PIN_ENABLE>;
				nvidia,enable-input = <TEGRA_PIN_ENABLE>;
			};
			lcd_dc1_pd2 {
				nvidia,pins = "lcd_dc1_pd2";
				nvidia,function = "displaya";
				nvidia,pull = <TEGRA_PIN_PULL_NONE>;
				nvidia,tristate = <TEGRA_PIN_ENABLE>;
				nvidia,enable-input = <TEGRA_PIN_ENABLE>;
			};
			pbb3 {
				nvidia,pins = "pbb3";
				nvidia,function = "vgp3";
				nvidia,pull = <TEGRA_PIN_PULL_NONE>;
				nvidia,tristate = <TEGRA_PIN_DISABLE>;
				nvidia,enable-input = <TEGRA_PIN_ENABLE>;
			};
			pbb7 {
				nvidia,pins = "pbb7";
				nvidia,function = "i2s4";
				nvidia,pull = <TEGRA_PIN_PULL_NONE>;
				nvidia,tristate = <TEGRA_PIN_DISABLE>;
				nvidia,enable-input = <TEGRA_PIN_ENABLE>;
			};
			drive_dap2 {
				nvidia,pins = "drive_dap2";
				nvidia,high-speed-mode = <TEGRA_PIN_DISABLE>;
				nvidia,schmitt = <TEGRA_PIN_ENABLE>;
				nvidia,nvidia,low-power-mode = <TEGRA_PIN_LP_DRIVE_DIV_1>;
				nvidia,pull-down-strength = <31>;
				nvidia,pull-up-strength = <31>;
				nvidia,slew-rate-rising = <TEGRA_PIN_SLEW_RATE_FASTEST>;
				nvidia,slew-rate-falling = <TEGRA_PIN_SLEW_RATE_FASTEST>;
			};
			drive_dap1 {
				nvidia,pins = "drive_dap1";
				nvidia,high-speed-mode = <TEGRA_PIN_DISABLE>;
				nvidia,schmitt = <TEGRA_PIN_ENABLE>;
				nvidia,nvidia,low-power-mode = <TEGRA_PIN_LP_DRIVE_DIV_1>;
				nvidia,pull-down-strength = <31>;
				nvidia,pull-up-strength = <31>;
				nvidia,slew-rate-rising = <TEGRA_PIN_SLEW_RATE_FASTEST>;
				nvidia,slew-rate-falling = <TEGRA_PIN_SLEW_RATE_FASTEST>;
			};
			drive_dbg {
				nvidia,pins = "drive_dbg";
				nvidia,high-speed-mode = <TEGRA_PIN_DISABLE>;
				nvidia,schmitt = <TEGRA_PIN_ENABLE>;
				nvidia,nvidia,low-power-mode = <TEGRA_PIN_LP_DRIVE_DIV_1>;
				nvidia,pull-down-strength = <31>;
				nvidia,pull-up-strength = <31>;
				nvidia,slew-rate-rising = <TEGRA_PIN_SLEW_RATE_FASTEST>;
				nvidia,slew-rate-falling = <TEGRA_PIN_SLEW_RATE_FASTEST>;
			};
			drive_at5 {
				nvidia,pins = "drive_at5";
				nvidia,high-speed-mode = <TEGRA_PIN_DISABLE>;
				nvidia,schmitt = <TEGRA_PIN_ENABLE>;
				nvidia,nvidia,low-power-mode = <TEGRA_PIN_LP_DRIVE_DIV_1>;
				nvidia,pull-down-strength = <31>;
				nvidia,pull-up-strength = <31>;
				nvidia,slew-rate-rising = <TEGRA_PIN_SLEW_RATE_FASTEST>;
				nvidia,slew-rate-falling = <TEGRA_PIN_SLEW_RATE_FASTEST>;
			};
			drive_gme {
				nvidia,pins = "drive_gme";
				nvidia,high-speed-mode = <TEGRA_PIN_DISABLE>;
				nvidia,schmitt = <TEGRA_PIN_ENABLE>;
				nvidia,nvidia,low-power-mode = <TEGRA_PIN_LP_DRIVE_DIV_1>;
				nvidia,pull-down-strength = <31>;
				nvidia,pull-up-strength = <31>;
				nvidia,slew-rate-rising = <TEGRA_PIN_SLEW_RATE_FASTEST>;
				nvidia,slew-rate-falling = <TEGRA_PIN_SLEW_RATE_FASTEST>;
			};
			drive_ddc {
				nvidia,pins = "drive_ddc";
				nvidia,high-speed-mode = <TEGRA_PIN_DISABLE>;
				nvidia,schmitt = <TEGRA_PIN_ENABLE>;
				nvidia,nvidia,low-power-mode = <TEGRA_PIN_LP_DRIVE_DIV_1>;
				nvidia,pull-down-strength = <31>;
				nvidia,pull-up-strength = <31>;
				nvidia,slew-rate-rising = <TEGRA_PIN_SLEW_RATE_FASTEST>;
				nvidia,slew-rate-falling = <TEGRA_PIN_SLEW_RATE_FASTEST>;
			};
			drive_ao1 {
				nvidia,pins = "drive_ao1";
				nvidia,high-speed-mode = <TEGRA_PIN_DISABLE>;
				nvidia,schmitt = <TEGRA_PIN_ENABLE>;
				nvidia,nvidia,low-power-mode = <TEGRA_PIN_LP_DRIVE_DIV_1>;
				nvidia,pull-down-strength = <31>;
				nvidia,pull-up-strength = <31>;
				nvidia,slew-rate-rising = <TEGRA_PIN_SLEW_RATE_FASTEST>;
				nvidia,slew-rate-falling = <TEGRA_PIN_SLEW_RATE_FASTEST>;
			};
			drive_uart3 {
				nvidia,pins = "drive_uart3";
				nvidia,high-speed-mode = <TEGRA_PIN_DISABLE>;
				nvidia,schmitt = <TEGRA_PIN_ENABLE>;
				nvidia,nvidia,low-power-mode = <TEGRA_PIN_LP_DRIVE_DIV_1>;
				nvidia,pull-down-strength = <31>;
				nvidia,pull-up-strength = <31>;
				nvidia,slew-rate-rising = <TEGRA_PIN_SLEW_RATE_FASTEST>;
				nvidia,slew-rate-falling = <TEGRA_PIN_SLEW_RATE_FASTEST>;
			};
			drive_sdio1 {
				nvidia,pins = "drive_sdio1";
				nvidia,high-speed-mode = <TEGRA_PIN_DISABLE>;
				nvidia,schmitt = <TEGRA_PIN_DISABLE>;
				nvidia,nvidia,low-power-mode = <TEGRA_PIN_LP_DRIVE_DIV_1>;
				nvidia,pull-down-strength = <46>;
				nvidia,pull-up-strength = <42>;
				nvidia,slew-rate-rising = <TEGRA_PIN_SLEW_RATE_FAST>;
				nvidia,slew-rate-falling = <TEGRA_PIN_SLEW_RATE_FAST>;
			};
			drive_sdio3 {
				nvidia,pins = "drive_sdio3";
				nvidia,high-speed-mode = <TEGRA_PIN_DISABLE>;
				nvidia,schmitt = <TEGRA_PIN_DISABLE>;
				nvidia,nvidia,low-power-mode = <TEGRA_PIN_LP_DRIVE_DIV_1>;
				nvidia,pull-down-strength = <46>;
				nvidia,pull-up-strength = <42>;
				nvidia,slew-rate-rising = <TEGRA_PIN_SLEW_RATE_FAST>;
				nvidia,slew-rate-falling = <TEGRA_PIN_SLEW_RATE_FAST>;
			};
			drive_gma {
				nvidia,pins = "drive_gma";
				nvidia,high-speed-mode = <TEGRA_PIN_DISABLE>;
				nvidia,schmitt = <TEGRA_PIN_DISABLE>;
				nvidia,nvidia,low-power-mode = <TEGRA_PIN_LP_DRIVE_DIV_1>;
				nvidia,pull-down-strength = <9>;
				nvidia,pull-up-strength = <9>;
				nvidia,slew-rate-rising = <TEGRA_PIN_SLEW_RATE_SLOWEST>;
				nvidia,slew-rate-falling = <TEGRA_PIN_SLEW_RATE_SLOWEST>;
			};
			drive_gmb {
				nvidia,pins = "drive_gmb";
				nvidia,high-speed-mode = <TEGRA_PIN_DISABLE>;
				nvidia,schmitt = <TEGRA_PIN_DISABLE>;
				nvidia,nvidia,low-power-mode = <TEGRA_PIN_LP_DRIVE_DIV_1>;
				nvidia,pull-down-strength = <9>;
				nvidia,pull-up-strength = <9>;
				nvidia,slew-rate-rising = <TEGRA_PIN_SLEW_RATE_SLOWEST>;
				nvidia,slew-rate-falling = <TEGRA_PIN_SLEW_RATE_SLOWEST>;
			};
			drive_gmc {
				nvidia,pins = "drive_gmc";
				nvidia,high-speed-mode = <TEGRA_PIN_DISABLE>;
				nvidia,schmitt = <TEGRA_PIN_DISABLE>;
				nvidia,nvidia,low-power-mode = <TEGRA_PIN_LP_DRIVE_DIV_1>;
				nvidia,pull-down-strength = <9>;
				nvidia,pull-up-strength = <9>;
				nvidia,slew-rate-rising = <TEGRA_PIN_SLEW_RATE_SLOWEST>;
				nvidia,slew-rate-falling = <TEGRA_PIN_SLEW_RATE_SLOWEST>;
			};
			drive_gmd {
				nvidia,pins = "drive_gmd";
				nvidia,high-speed-mode = <TEGRA_PIN_DISABLE>;
				nvidia,schmitt = <TEGRA_PIN_DISABLE>;
				nvidia,nvidia,low-power-mode = <TEGRA_PIN_LP_DRIVE_DIV_1>;
				nvidia,pull-down-strength = <9>;
				nvidia,pull-up-strength = <9>;
				nvidia,slew-rate-rising = <TEGRA_PIN_SLEW_RATE_SLOWEST>;
				nvidia,slew-rate-falling = <TEGRA_PIN_SLEW_RATE_SLOWEST>;
			};
		};
	};*/

	pwm@7000a000 {
		status = "okay";
	};

	sound {
		compatible = "nvidia,tegra-audio-wm8903-cardhu",
			     "nvidia,tegra-audio-wm8903";
		nvidia,model = "NVIDIA Tegra Cardhu";

		nvidia,audio-routing =
			"Headphone Jack", "HPOUTR",
			"Headphone Jack", "HPOUTL",
			"Int Spk", "ROP",
			"Int Spk", "RON",
			"Int Spk", "LOP",
			"Int Spk", "LON",
			"Mic Jack", "MICBIAS",
			"IN1L", "Mic Jack";

		nvidia,i2s-controller = <&tegra_i2s1>;
		nvidia,audio-codec = <&wm8903>;

		nvidia,spkr-en-gpios = <&wm8903 2 GPIO_ACTIVE_HIGH>;
		nvidia,hp-det-gpios = <&gpio TEGRA_GPIO(W, 2)
			GPIO_ACTIVE_HIGH>;

		clocks = <&tegra_car TEGRA30_CLK_PLL_A>,
			 <&tegra_car TEGRA30_CLK_PLL_A_OUT0>,
			 <&tegra_car TEGRA30_CLK_EXTERN1>;
		clock-names = "pll_a", "pll_a_out0", "mclk";
	};

	gpio_keys {
		compatible = "gpio-keys";
		#address-cells = <1>;
		#size-cells = <0>;
		/*autorepeat;*/
		button@1 {
			label = "Power";
			linux,code = <116>;
			gpios = <&gpio TEGRA_GPIO(V, 0) GPIO_ACTIVE_LOW>;
			wakeup-source;
		};
		button@2 {
			label = "Volume up";
			linux,code = <115>;
			gpios = <&gpio TEGRA_GPIO(Q, 2) GPIO_ACTIVE_LOW>;
		};
		button@3 {
			label = "Volume down";
			linux,code = <114>;
			gpios = <&gpio TEGRA_GPIO(Q, 3) GPIO_ACTIVE_LOW>;
		};
	};

	/* I2C1 */
	panelddc: i2c@7000c000 {
		status = "okay";
		clock-frequency = <100000>;
	};

	/* I2C2 */
	i2c@7000c400 {
		status = "okay";
		clock-frequency = <400000>;

		touchscreen@10 {
			compatible = "elan,ekth3500";
			reg = <0x10>;
			interrupt-parent = <&gpio>;
			interrupts = <TEGRA_GPIO(H, 4) IRQ_TYPE_EDGE_FALLING>;
			reset-gpios = <&gpio TEGRA_GPIO(H, 6) GPIO_ACTIVE_LOW>;
			wakeup-source;
			touchscreen-inverted-y;
			touchscreen-size-x = <2240>;
			touchscreen-size-y = <1408>;
			touchscreen-fuzz-x = <5>;
			touchscreen-fuzz-y = <5>;
		};

		pad_ec: asusec@15 {
			compatible = "asus,ec";
			reg = <0x15>;
			interrupt-parent = <&gpio>;
			interrupts = <TEGRA_GPIO(S, 2) IRQ_TYPE_LEVEL_LOW>;
			ec-request-gpios = <&gpio TEGRA_GPIO(Q, 1) GPIO_ACTIVE_LOW>;
			asus,dockram = <&pad_dockram>;
		};

		pad_dockram: dockram@17 {
			compatible = "asus,ec-dockram";
			reg = <0x17>;
		};

		dock_ec: asusec@19 {
			compatible = "asus,ec";
			reg = <0x19>;
			interrupt-parent = <&gpio>;
			interrupts = <TEGRA_GPIO(S, 7) IRQ_TYPE_LEVEL_LOW>;
			ec-request-gpios = <&gpio TEGRA_GPIO(Q, 6) GPIO_ACTIVE_LOW>;
			dock-detect-gpios = <&gpio TEGRA_GPIO(U, 4) GPIO_ACTIVE_LOW>;
			asus,dockram = <&dock_dockram>;
			asus,has-keyboard;
		};

		dock_dockram: dockram@1b {
			compatible = "asus,ec-dockram";
			reg = <0x1b>;
		};
	};

	/* I2C3 */
	i2c@7000c500 {
		status = "okay";
		clock-frequency = <400000>;

		/* ALS and Proximity sensor */
	/*	isl29028@44 {
			compatible = "isil,isl29028";
			reg = <0x44>;
			interrupt-parent = <&gpio>;
			interrupts = <TEGRA_GPIO(L, 0) IRQ_TYPE_LEVEL_HIGH>;
		};

		i2cmux@70 {
			compatible = "nxp,pca9546";
			#address-cells = <1>;
			#size-cells = <0>;
			reg = <0x70>;
		};*/
	};

	/* I2C4 */
	i2c@7000c700 {
		status = "okay";
		clock-frequency = <93750>;
	};

	/* I2C5 */
	i2c@7000d000 {
		status = "okay";
		clock-frequency = <400000>;

		wm8903: wm8903@1a {
			compatible = "wlf,wm8903";
			reg = <0x1a>;
			interrupt-parent = <&gpio>;
			interrupts = <TEGRA_GPIO(W, 3) IRQ_TYPE_LEVEL_HIGH>;

			gpio-controller;
			#gpio-cells = <2>;

			micdet-cfg = <0>;
			micdet-delay = <100>;
			gpio-cfg = <0xffffffff 0xffffffff 0 0xffffffff 0xffffffff>;
		};

		pmic: tps65911@2d {
			compatible = "ti,tps65911";
			reg = <0x2d>;

			interrupts = <GIC_SPI 86 IRQ_TYPE_LEVEL_HIGH>;
			#interrupt-cells = <2>;
			interrupt-controller;

			ti,system-power-controller;

			#gpio-cells = <2>;
			gpio-controller;

			vcc1-supply = <&vdd_ac_bat_reg>;
			vcc2-supply = <&vdd_ac_bat_reg>;
			vcc3-supply = <&vio_reg>;
			vcc4-supply = <&en_5v0_a04>;
			vcc5-supply = <&vdd_ac_bat_reg>;
			vcc6-supply = <&vdd2_reg>;
			vcc7-supply = <&vdd_ac_bat_reg>;
			vccio-supply = <&vdd_ac_bat_reg>;

			regulators {
				vdd1_reg: vdd1 {
					regulator-name = "vddio_ddr_1v2";
					regulator-min-microvolt = <1200000>;
					regulator-max-microvolt = <1200000>;
					regulator-always-on;
				};

				vdd2_reg: vdd2 {
					regulator-name = "vdd_1v5_gen";
					regulator-min-microvolt = <1500000>;
					regulator-max-microvolt = <1500000>;
					regulator-always-on;
				};

				vddctrl_reg: vddctrl {
					regulator-name = "vdd_cpu,vdd_sys";
					regulator-min-microvolt = <800000>;
					regulator-max-microvolt = <1100000>;
					regulator-boot-on;
					regulator-always-on;
				};

				vio_reg: vio {
					regulator-name = "vdd_1v8_gen";
					regulator-min-microvolt = <1800000>;
					regulator-max-microvolt = <1800000>;
					regulator-always-on;
				};

				ldo1_reg: ldo1 {
					regulator-name = "vddio_emmc"; /* "vddio_sdmmc", "sdhci-tegra.3" */
					regulator-min-microvolt = <3300000>;
					regulator-max-microvolt = <3300000>;
				};

				sd_slot_reg: ldo2 {
					regulator-name = "vddio_sd_slot"; /* "vddio_sd_slot", "sdhci-tegra.0" */
					regulator-min-microvolt = <3100000>;
					regulator-max-microvolt = <3140000>;
					regulator-always-on;
				};

				ldo3_reg: ldo3 {
					regulator-name = "vddio_sd_sdmmc"; /* "vddio_sd_slot", "sdhci-tegra.0" */
					regulator-min-microvolt = <2900000>;
					regulator-max-microvolt = <2940000>;
					regulator-always-on;
				};

				/* LDO3 is not connected to anything */  // "vddio_sdmmc", "sdhci-tegra.0" only in e118x e1198 unused

				ldo4_reg: ldo4 {
					regulator-name = "vdd_rtc";
					regulator-min-microvolt = <1200000>;
					regulator-max-microvolt = <1200000>;
					regulator-always-on;
				};

				ldo5_reg: ldo5 {
					regulator-name = "vddio_sdmmc,avdd_vdac"; // "vddio_sdmmc", "sdhci-tegra.0" on e1198
					regulator-min-microvolt = <3300000>;
					regulator-max-microvolt = <3300000>;
					regulator-always-on;
				};

				ldo6_reg: ldo6 {
					regulator-name = "avdd_dsi_csi,pwrdet_mipi";
					regulator-min-microvolt = <1200000>;
					regulator-max-microvolt = <1200000>;
				};

				ldo7_reg: ldo7 {
					regulator-name = "vdd_pllm,x,u,a_p_c_s";
					regulator-min-microvolt = <1200000>;
					regulator-max-microvolt = <1200000>;
					regulator-always-on;
				};

				ldo8_reg: ldo8 {
					regulator-name = "vdd_ddr_hs";
					regulator-min-microvolt = <1000000>;
					regulator-max-microvolt = <1000000>;
					regulator-always-on;
				};
			};
		};

	/*	temperature-sensor@4c {
			compatible = "onnn,nct1008";
			reg = <0x4c>;
			vcc-supply = <&sys_3v3_reg>;
			interrupt-parent = <&gpio>;
			interrupts = <TEGRA_GPIO(CC, 2) IRQ_TYPE_LEVEL_LOW>;
		};*/

		tps62361@60 {
			compatible = "ti,tps62361";
			reg = <0x60>;

			regulator-name = "tps62361-vout,vdd_core";
			regulator-min-microvolt = <500000>;
			regulator-max-microvolt = <1500000>;
			regulator-boot-on;
			regulator-always-on;
			ti,vsel0-state-high;
			ti,vsel1-state-high;
		};
	};

	pmc@7000e400 {
		status = "okay";
		nvidia,invert-interrupt;
		nvidia,suspend-mode = <1>;
		nvidia,cpu-pwr-good-time = <2000>;
		nvidia,cpu-pwr-off-time = <200>;
		nvidia,core-pwr-good-time = <3845 3845>;
		nvidia,core-pwr-off-time = <0>;
		nvidia,core-power-req-active-high;
		nvidia,sys-clock-req-active-high;
	};

	ahub@70080000 {
		i2s@70080400 {
			status = "okay";
		};
	};

	/* SDMMC1 */
	sdhci@78000000 {
		status = "okay";
		cd-gpios = <&gpio TEGRA_GPIO(I, 5) GPIO_ACTIVE_LOW>;
		/*wp-gpios = <&gpio TEGRA_GPIO(T, 3) GPIO_ACTIVE_HIGH>;*/
		/*vmmc-supply = <&ldo3_reg>;*/
		bus-width = <4>;
		no-1-8-v;
	};

	/* SDMMC2 is ignored by stock kernel */

	sdio_pwrseq: sdio-pwrseq {
		compatible = "mmc-pwrseq-simple";
		clocks = <&clk32k_in>;
		clock-names = "ext_clock";
		reset-gpios = <&gpio TEGRA_GPIO(D, 3) GPIO_ACTIVE_LOW>;
	};

	/* SDMMC3 */
	sdhci@78000400 {
		status = "okay";
		power-gpios = <&gpio TEGRA_GPIO(D, 4) GPIO_ACTIVE_HIGH>;
		mmc-pwrseq = <&sdio_pwrseq>;
		bus-width = <4>;
		non-removable;

		brcmf: bcrmf@1 {
			compatible = "brcm,bcm4329-fmac";
			/*interrupt-parent = <&gpio>;
			interrupts = <TEGRA_GPIO(O, 4) IRQ_TYPE_LEVEL_LOW>;
			interrupt-names = "host-wake";*/
		};
	};

	/* SDMMC4 */
	sdhci@78000600 {
		status = "okay";
		bus-width = <8>;
		non-removable;
		/*vmmc-supply = <&ldo1_reg>;*/
		no-1-8-v;
	};

	usb@7d008000 {
		status = "okay";
	};

	usb-phy@7d008000 {
		/*vbus-supply = <&usb3_vbus_reg>;*/
		status = "okay";
	};

	backlight: backlight {
		compatible = "pwm-backlight";

		enable-gpios = <&gpio TEGRA_GPIO(H, 2) GPIO_ACTIVE_HIGH>;
		power-supply = <&en_vdd_bl>;
		pwms = <&pwm 0 5100000>;

		brightness-levels = <0 4 8 16 32 64 128 255>;
		default-brightness-level = <6>;
	};

	clocks {
		compatible = "simple-bus";
		#address-cells = <1>;
		#size-cells = <0>;

		clk32k_in: clock@0 {
			compatible = "fixed-clock";
			reg=<0>;
			#clock-cells = <0>;
			clock-frequency = <32768>;
		};
	};

	panel: panel {
		compatible = "hannstar,hsd101pww1", "hannstar,hsd070pww1", "simple-panel";
		/*ddc-i2c-bus = <&panelddc>;*/

		power-supply = <&en_vdd_pnl1>;
		enable-gpios = <&gpio TEGRA_GPIO(L, 2) GPIO_ACTIVE_HIGH>;

		backlight = <&backlight>;
	};

	regulators {
		compatible = "simple-bus";
		#address-cells = <1>;
		#size-cells = <0>;

		en_5v_cp: regulator@0 {
			compatible = "regulator-fixed";
			reg = <0>;
			regulator-name = "en_5v_cp";
			regulator-min-microvolt = <5000000>;
			regulator-max-microvolt = <5000000>;
			regulator-always-on;
			regulator-boot-on;
			enable-active-high;
			gpio = <&pmic 0 GPIO_ACTIVE_HIGH>;
		};

		en_5v0_a04: regulator@1 {
			compatible = "regulator-fixed";
			reg = <1>;
			regulator-name = "en_5v0";
			regulator-min-microvolt = <5000000>;
			regulator-max-microvolt = <5000000>;
			enable-active-high;
			regulator-always-on;
			gpio = <&pmic 8 GPIO_ACTIVE_HIGH>;
		};

		en_ddr_a04: regulator@2 {
			compatible = "regulator-fixed";
			regulator-name = "en_ddr";
			reg = <2>;
			regulator-min-microvolt = <1500000>;
			regulator-max-microvolt = <1500000>;
			regulator-always-on;
			regulator-boot-on;
			enable-active-high;
			gpio = <&pmic 7 GPIO_ACTIVE_HIGH>;
		};

		en_3v3_sys_a04: regulator@3 {
			compatible = "regulator-fixed";
			reg = <3>;
			regulator-name = "en_3v3_sys";
			regulator-min-microvolt = <3300000>;
			regulator-max-microvolt = <3300000>;
			enable-active-high;
			regulator-always-on;
			regulator-boot-on;
			gpio = <&pmic 6 GPIO_ACTIVE_HIGH>;
		};

		/* not needed on TF300T ? */
		en_3v3_modem: regulator@4 {
			compatible = "regulator-fixed";
			reg = <4>;
			regulator-name = "en_3v3_modem";
			regulator-min-microvolt = <3300000>;
			regulator-max-microvolt = <3300000>;
			/* regulator-always-on; */
			enable-active-high;
			gpio = <&gpio TEGRA_GPIO(D, 6) GPIO_ACTIVE_HIGH>;
		};

		cam1_ldo_en: regulator@5 {
				compatible = "regulator-fixed";
				reg = <5>;
				regulator-name = "cam1_ldo_en";
				regulator-min-microvolt = <2800000>;
				regulator-max-microvolt = <2800000>;
				enable-active-high;
				gpio = <&gpio TEGRA_GPIO(R, 6) GPIO_ACTIVE_HIGH>;
				vin-supply = <&en_3v3_sys_a04>;
		};

		cam3_ldo_en: regulator@6 {
				compatible = "regulator-fixed";
				reg = <6>;
				regulator-name = "cam3_ldo_en";
				regulator-min-microvolt = <3300000>;
				regulator-max-microvolt = <3300000>;
				enable-active-high;
				gpio = <&gpio TEGRA_GPIO(S, 0) GPIO_ACTIVE_HIGH>;
				vin-supply = <&en_3v3_sys_a04>;
		};

		en_vdd_com: regulator@7 {
				compatible = "regulator-fixed";
				reg = <7>;
				regulator-name = "en_vdd_com";
				regulator-min-microvolt = <3300000>;
				regulator-max-microvolt = <3300000>;
				enable-active-high;
				gpio = <&gpio TEGRA_GPIO(D, 0) GPIO_ACTIVE_HIGH>;
				vin-supply = <&en_3v3_sys_a04>;
		};

		en_3v3_fuse_pm269: regulator@8 {
				compatible = "en_3v3_fuse";
				reg = <8>;
				regulator-name = "cam1_ldo";
				regulator-min-microvolt = <3300000>;
				regulator-max-microvolt = <3300000>;
				enable-active-high;
				gpio = <&gpio TEGRA_GPIO(C, 1) GPIO_ACTIVE_HIGH>;
				vin-supply = <&en_3v3_sys_a04>;
		};

		en_3v3_emmc: regulator@9 {
			compatible = "regulator-fixed";
			reg = <9>;
			regulator-name = "en_3v3_emmc";
			regulator-min-microvolt = <3300000>;
			regulator-max-microvolt = <3300000>;
			regulator-always-on;
			enable-active-high;
			gpio = <&gpio TEGRA_GPIO(D, 1) GPIO_ACTIVE_HIGH>;
			vin-supply = <&en_3v3_sys_a04>;
		};

		en_1v8_cam: regulator@10 {
			compatible = "regulator-fixed";
			reg = <10>;
			regulator-name = "en_1v8_cam";
			regulator-min-microvolt = <1800000>;
			regulator-max-microvolt = <1800000>;
			enable-active-high;
			gpio = <&gpio TEGRA_GPIO(BB, 4) GPIO_ACTIVE_HIGH>;
			vin-supply = <&vio_reg>;
		};

		/* en_vbrtr is present in stock kernel but doesn't sound
		 * but TF300X devices have no vibrator */






		vdd_ac_bat_reg: regulator@11 {
			compatible = "regulator-fixed";
			reg = <11>;
			regulator-name = "vdd_ac_bat";
			regulator-min-microvolt = <5000000>;
			regulator-max-microvolt = <5000000>;
			regulator-always-on;
		};





		/*
		 TODO : Check wether we really have a PM313 display board
		*/


		en_vdd_pnl1: regulator@12 {
			compatible = "regulator-fixed";
			reg = <12>;
			regulator-name = "en_vdd_pnl1";
			regulator-min-microvolt = <3300000>;
			regulator-max-microvolt = <3300000>;
			enable-active-high;
			regulator-always-on;
			regulator-boot-on;
			gpio = <&gpio TEGRA_GPIO(W, 1) GPIO_ACTIVE_HIGH>;
			vin-supply = <&en_3v3_sys_a04>;
		};

		en_vdd_bl: regulator@13 {
			compatible = "regulator-fixed";
			reg = <13>;
			regulator-name = "en_vdd_bl";
			regulator-min-microvolt = <5000000>;
			regulator-max-microvolt = <5000000>;
			enable-active-high;
			regulator-always-on;
			regulator-boot-on;
			gpio = <&gpio TEGRA_GPIO(H, 3) GPIO_ACTIVE_HIGH>;
		};







	};

};
